AUTOSAR XML (schema 4-3-0)
package /CAN1/ISignalGroup
  36 x i signal group:
    CAN1_SG_AC_BTMS_C1000_0: i-signal=[CAN1_ACAmbTemp, CAN1_ACCabinTemp, CAN1_THCM_Reserve1_Sta, CAN1_THCM_Reserve2_Sta, CAN1_THCM_Reserve3_Sta, CAN1_THCM_Reserve4_Sta], system-signal-group=CAN1_SG_AC_BTMS_C1000_0
    CAN1_SG_AC_BTMS_C1000_1: i-signal=[CAN1_ACFanSpdSta, CAN1_ACMODESta, CAN1_ACPwrSta, CAN1_THCM_Outcycle_Sta, CAN1_THCM_Reserve10_Sta, CAN1_THCM_Reserve11_Sta, CAN1_THCM_Reserve12_Sta, CAN1_THCM_Reserve13_Sta, CAN1_THCM_Reserve5_Sta, CAN1_THCM_Reserve6_Sta, CAN1_THCM_Reserve7_Sta, CAN1_THCM_Reserve8_Sta, CAN1_THCM_Reserve9_Sta], system-signal-group=CAN1_SG_AC_BTMS_C1000_1
    CAN1_SG_AC_BTMS_C1000_2: i-signal=CAN1_THCM_Faultlv_Sta, system-signal-group=CAN1_SG_AC_BTMS_C1000_2
    CAN1_SG_AC_BTMS_C1000_4: i-signal=[CAN1_TM2BFaultCode, CAN1_TM2BFaultLv, CAN1_TM2BInletTemp, CAN1_TM2BOutletTemp, CAN1_TM2BRQPower, CAN1_TM2BTMSHVRlySta, CAN1_TM2BWorkStatus], system-signal-group=CAN1_SG_AC_BTMS_C1000_4
    CAN1_SG_AC_BTMS_C5000_0: i-signal=CAN1_ACTempSetSta, system-signal-group=CAN1_SG_AC_BTMS_C5000_0
    CAN1_SG_ASC1_A: i-signal=CAN1_ASC1KneelingInfo, system-signal-group=CAN1_SG_ASC1_A
    CAN1_SG_EBC1: i-signal=[CAN1_ABSFullyOper, CAN1_ABSOffroadSw, CAN1_ASRBrakeCtrlAtc, CAN1_ASREngCtrlAtc, CAN1_ASRHillHolderSw, CAN1_ASROffroadSw, CAN1_ATCASRInfoSig, CAN1_AcltrInterlockSw, CAN1_AntiLBrakABSAct, CAN1_BrakePedalPos, CAN1_EBSAmWarnLampSta, CAN1_EBSBrakeSw, CAN1_EBSRedWarnLampSta, CAN1_EngAuxShutdownSw, CAN1_EngDerateSw, CAN1_EngRetSel, CAN1_HaltBrakeSw, CAN1_RmAccelEnSw, CAN1_SACtrlBrakeCtrl, CAN1_TractCtrlOvrSw, CAN1_TrailerABSSta, CAN1_TrailerABSWarnSig], system-signal-group=CAN1_SG_EBC1
    CAN1_SG_EBC2: i-signal=[CAN1_FASpeed, CAN1_RelaSpdFALWheel, CAN1_RelaSpdFARWheel, CAN1_RelaSpdRA1LWheel, CAN1_RelaSpdRA1RWheel, CAN1_RelaSpdRA2LWheel, CAN1_RelaSpdRA2RWheel], system-signal-group=CAN1_SG_EBC2
    CAN1_SG_EBC5: i-signal=[CAN1_BrkTempeWarn, CAN1_EmhBrkAct, CAN1_FndBrkUse, CAN1_HaltBrkMode, CAN1_HillHolderMode, CAN1_ParkBrkActuFAct, CAN1_RailroadMode, CAN1_XBRAcltnLimit, CAN1_XBRActtrlMode, CAN1_XBRSysSta], system-signal-group=CAN1_SG_EBC5
    CAN1_SG_ECAS_DM1: i-signal=CAN1_ECASAWarmLampSta, system-signal-group=CAN1_SG_ECAS_DM1
    CAN1_SG_EMC1_EM1: i-signal=[CAN1_EM1CS, CAN1_EM1Cnt, CAN1_EM1OvrCtrlMBrk, CAN1_EM1OvrCtrlMDriv, CAN1_EM1OvrCtrlMPriBrk, CAN1_EM1OvrCtrlMPriDriv, CAN1_EM1ReqTorqHRlsBrk, CAN1_EM1ReqTorqHRlsDri, CAN1_EM1ReqTorqLimBrk, CAN1_EM1ReqTorqLimDriv], system-signal-group=CAN1_SG_EMC1_EM1
    CAN1_SG_FD1_C1000_0: i-signal=[CAN1_AirPressureFC2, CAN1_AirPressurePC3, CAN1_AirPressureRC1], system-signal-group=CAN1_SG_FD1_C1000_0
    CAN1_SG_FD1_C100_0: i-signal=CAN1_VCUEBSRd4BR, system-signal-group=CAN1_SG_FD1_C100_0
    CAN1_SG_FD1_C100_1: i-signal=[CAN1_VCUEBSHBSw, CAN1_VCUEBSHHSw], system-signal-group=CAN1_SG_FD1_C100_1
    CAN1_SG_FD1_C100_2: i-signal=[CAN1_GearFlashInd, CAN1_LVBattLow, CAN1_PweLmtInd, CAN1_VCUBCMBuzzReq, CAN1_VCUDTCCurrCode, CAN1_VCUDTCCurrSta, CAN1_VCUDTCHisCode, CAN1_VCUDTCHisSta, CAN1_VCUKeyStatus, CAN1_VCUWarnInd, CAN1_VCUnoPBInd], system-signal-group=CAN1_SG_FD1_C100_2
    CAN1_SG_FD1_C100_3: i-signal=[CAN1_BrakeSW, CAN1_VCUVehSpd], system-signal-group=CAN1_SG_FD1_C100_3
    CAN1_SG_CGW_FD1_C100_3: i-signal=CAN1_ParkBrakeSW, system-signal-group=CAN1_SG_CGW_FD1_C100_3
    CAN1_SG_FD1_C10_0: i-signal=CAN1_VehActDriveDirect, system-signal-group=CAN1_SG_FD1_C10_0
    CAN1_SG_FD1_C10_1: i-signal=[CAN1_ActEMOutSftSpd, CAN1_ActEMpTrq, CAN1_ActEMpTrqHrls, CAN1_ActMaxAvaEMRecpTrq, CAN1_DrvDemEMRtapTrq, CAN1_EMTrqModeDrvBrk, CAN1_RetSelNonEng, CAN1_SACtrlDev], system-signal-group=CAN1_SG_FD1_C10_1
    CAN1_SG_FD1_C200_0: i-signal=CAN1_SysPowerMode, system-signal-group=CAN1_SG_FD1_C200_0
    CAN1_SG_FD1_C20_0: i-signal=[CAN1_DCCurr, CAN1_DCVol, CAN1_MaxTorqAvail, CAN1_MinTorqAvail], system-signal-group=CAN1_SG_FD1_C20_0
    CAN1_SG_FD1_C250_0: i-signal=[CAN1_EMParasLoss, CAN1_NFricPercTorq], system-signal-group=CAN1_SG_FD1_C250_0
    CAN1_SG_FD1_C5000_0: i-signal=[CAN1_RC1MaxRetSpdP2, CAN1_RC1PctTrqIdleP1, CAN1_RC1PctTrqMaxSpdP2, CAN1_RC1PctTrqP3, CAN1_RC1PctTrqP4, CAN1_RC1PctTrqPekTrqP5, CAN1_RC1RefRetTrq, CAN1_RC1RetCtrlMth, CAN1_RC1RetLocat, CAN1_RC1RetSpdIdleP1, CAN1_RC1RetSpdP3, CAN1_RC1RetSpdP4, CAN1_RC1RetSpdPekTrqP5, CAN1_RC1RetType], system-signal-group=CAN1_SG_FD1_C5000_0
    CAN1_SG_FD1_C5000_1: i-signal=[CAN1_EMDefTrqLmt, CAN1_EMEMRefTorq, CAN1_EMEMSpdP2, CAN1_EMEMSpdP3, CAN1_EMEMSpdP4, CAN1_EMEMSpdP5, CAN1_EMExtRSCtrlUpLmt, CAN1_EMGainEndSpdGvn, CAN1_EMMaxMEngOvrSP7, CAN1_EMMaxMOvrTLmt, CAN1_EMMomOfInertia, CAN1_EMPercTorqIdleP1, CAN1_EMPercTorqP2, CAN1_EMPercTorqP3, CAN1_EMPercTorqP4, CAN1_EMPercTorqP5, CAN1_EMReqSpdCtrlLoLmt, CAN1_EMReqSpdCtrlUpLmt, CAN1_EMReqTrqCtrlLoLmt, CAN1_EMReqTrqCtrlUpLmt, CAN1_EMSpdHIdleP6, CAN1_EMSpdIdleP1, CAN1_EMSupTSC1CtrlPG1, CAN1_EMSupTSC1CtrlPG2, CAN1_EMSupTSC1CtrlPG3, CAN1_EMSupTSC1CtrlPG4, CAN1_EMSupVarRTSC1MSG], system-signal-group=CAN1_SG_FD1_C5000_1
    CAN1_SG_FD1_C50_0: i-signal=CAN1_ActDriveDirect, system-signal-group=CAN1_SG_FD1_C50_0
    CAN1_SG_FD1_C50_1: i-signal=[CAN1_AccPedal1LowSW, CAN1_AccPedalPos1, CAN1_EEC2MSGCS, CAN1_EEC2MSGCnt], system-signal-group=CAN1_SG_FD1_C50_1
    CAN1_SG_FD1_C80_0: i-signal=[CAN1_DLEngaged, CAN1_ShiftPgs], system-signal-group=CAN1_SG_FD1_C80_0
    CAN1_SG_FD1_CE100_0: i-signal=[CAN1_CFGEM1DT0, CAN1_CFGEM1DT1, CAN1_CFGEM1DT2, CAN1_CFGEM1DT3, CAN1_CFGEM1DT4, CAN1_CFGEM1DT5, CAN1_CFGEM1DT6, CAN1_CFGEM1DT7], system-signal-group=CAN1_SG_FD1_CE100_0
    CAN1_SG_FD1_CE100_1: i-signal=[CAN1_CFGEM1BAMPGN, CAN1_CFGEM1BAMRsv, CAN1_CFGEM1BAMTNum, CAN1_CFGEM1BAMTSize, CAN1_CFGEM1Ctrl], system-signal-group=CAN1_SG_FD1_CE100_1
    CAN1_SG_FD1_CE100_2: i-signal=[CAN1_FDC_BCM_DVRSignalL_Cmd, CAN1_FDC_BCM_DVRSignalR_Cmd, CAN1_FDC_BCM_LTurnLp_Cmd, CAN1_FDC_BCM_RTurnLp_Cmd], system-signal-group=CAN1_SG_FD1_CE100_2
    CAN1_SG_HRW: i-signal=[CAN1_WhlSpeed_FL, CAN1_WhlSpeed_FR, CAN1_WhlSpeed_RL, CAN1_WhlSpeed_RR], system-signal-group=CAN1_SG_HRW
    CAN1_SG_TC1: i-signal=[CAN1_DrivDirF, CAN1_DrivDirN, CAN1_DrivDirR, CAN1_LifeCnt, CAN1_TransReqGear], system-signal-group=CAN1_SG_TC1
    CAN1_SG_TPMS1: i-signal=[CAN1_LBIBatWarn, CAN1_LBIPressIndi, CAN1_LBISensorFail, CAN1_LBIWheelTmpIndi, CAN1_LBOBatWarn, CAN1_LBOPressIndi, CAN1_LBOSensorFail, CAN1_LBOWheelTmpIndi, CAN1_LFBatWarn, CAN1_LFPressIndi, CAN1_LFSensorFail, CAN1_LFWheelTmpIndi, CAN1_RBIBatWarn, CAN1_RBIPressIndi, CAN1_RBISensorFail, CAN1_RBIWheelTmpIndi, CAN1_RBOBatWarn, CAN1_RBOPressIndi, CAN1_RBOSensorFail, CAN1_RBOWheelTmpIndi, CAN1_RFBatWarn, CAN1_RFPressIndi, CAN1_RFSensorFail, CAN1_RFWheelTmpIndi, CAN1_TPMSWarnIndi], system-signal-group=CAN1_SG_TPMS1
    CAN1_SG_TPMS2: i-signal=[CAN1_LBIWheelPress, CAN1_LBOWheelPress, CAN1_LFWheelPress, CAN1_RBIWheelPress, CAN1_RBOWheelPress, CAN1_RFWheelPress], system-signal-group=CAN1_SG_TPMS2
    CAN1_SG_TPMS3: i-signal=[CAN1_LBIWheelTemp, CAN1_LBOWheelTemp, CAN1_LFWheelTemp, CAN1_RBIWheelTemp, CAN1_RBOWheelTemp, CAN1_RFWheelTemp], system-signal-group=CAN1_SG_TPMS3
    CAN1_SG_VDC1: i-signal=CAN1_VDCBrakeLightReq, system-signal-group=CAN1_SG_VDC1
package /CAN1/Cluster
  can cluster CAN1: baudrate=500
    can physical channel CAN1: comm-connectors=ConnCAN1
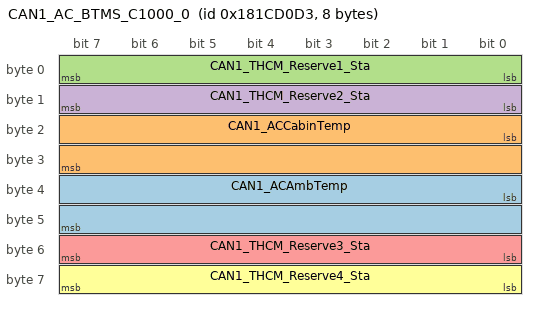
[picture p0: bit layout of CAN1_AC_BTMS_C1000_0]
      frame CAN1_AC_BTMS_C1000_0: id 0x181CD0D3, frame-length=8, can-addressing-mode=EXTENDED, can-fd-frame-support=false, can-frame-rx-behavior=CAN-20, can-frame-tx-behavior=CAN-20
        pdu CAN1_AC_BTMS_C1000_0: length=8, minimum-delay=0.0, transmission-mode-true-timing=cyclic-timing=time-period=1, unused-bit-pattern=0
          mapping CAN1_SG_AC_BTMS_C1000_0: i-signal-group=CAN1_SG_AC_BTMS_C1000_0, start-position=0, transfer-property=PENDING
          signal CAN1_ACAmbTemp: start 32, 16 bit, little-endian, i-signal-type=PRIMITIVE, init-value=constant-reference=Init_CAN1_ACAmbTemp, base-type=uint16, implementation-data-type=uint16, transfer-property=PENDING
          signal CAN1_ACCabinTemp: start 16, 16 bit, little-endian, i-signal-type=PRIMITIVE, init-value=constant-reference=Init_CAN1_ACCabinTemp, base-type=uint16, implementation-data-type=uint16, transfer-property=PENDING
          signal CAN1_THCM_Reserve1_Sta: start 0, 8 bit, little-endian, i-signal-type=PRIMITIVE, init-value=constant-reference=Init_CAN1_THCM_Reserve1_Sta, base-type=uint8, implementation-data-type=uint8, transfer-property=PENDING
          signal CAN1_THCM_Reserve2_Sta: start 8, 8 bit, little-endian, i-signal-type=PRIMITIVE, init-value=constant-reference=Init_CAN1_THCM_Reserve2_Sta, base-type=uint8, implementation-data-type=uint8, transfer-property=PENDING
          signal CAN1_THCM_Reserve3_Sta: start 48, 8 bit, little-endian, i-signal-type=PRIMITIVE, init-value=constant-reference=Init_CAN1_THCM_Reserve3_Sta, base-type=uint8, implementation-data-type=uint8, transfer-property=PENDING
          signal CAN1_THCM_Reserve4_Sta: start 56, 8 bit, little-endian, i-signal-type=PRIMITIVE, init-value=constant-reference=Init_CAN1_THCM_Reserve4_Sta, base-type=uint8, implementation-data-type=uint8, transfer-property=PENDING
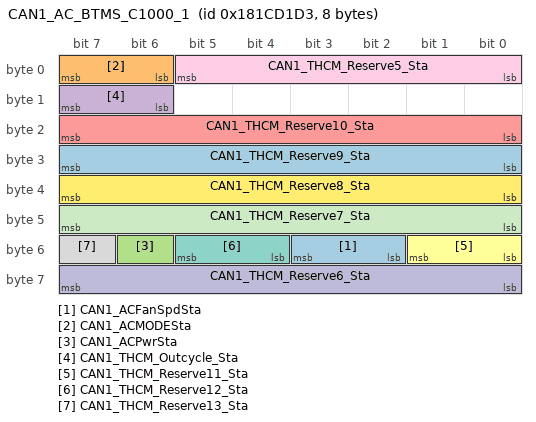
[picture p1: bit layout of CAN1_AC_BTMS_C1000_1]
      frame CAN1_AC_BTMS_C1000_1: id 0x181CD1D3, frame-length=8, can-addressing-mode=EXTENDED, can-fd-frame-support=false, can-frame-rx-behavior=CAN-20, can-frame-tx-behavior=CAN-20
        pdu CAN1_AC_BTMS_C1000_1: length=8, minimum-delay=0.0, transmission-mode-true-timing=cyclic-timing=time-period=1, unused-bit-pattern=0
          mapping CAN1_SG_AC_BTMS_C1000_1: i-signal-group=CAN1_SG_AC_BTMS_C1000_1, start-position=0, transfer-property=PENDING
          signal CAN1_ACFanSpdSta: start 50, 2 bit, little-endian, i-signal-type=PRIMITIVE, init-value=constant-reference=Init_CAN1_ACFanSpdSta, base-type=uint8, implementation-data-type=uint8, transfer-property=PENDING
          signal CAN1_ACMODESta: start 6, 2 bit, little-endian, i-signal-type=PRIMITIVE, init-value=constant-reference=Init_CAN1_ACMODESta, base-type=uint8, implementation-data-type=uint8, transfer-property=PENDING
          signal CAN1_ACPwrSta: start 54, 1 bit, little-endian, i-signal-type=PRIMITIVE, init-value=constant-reference=Init_CAN1_ACPwrSta, base-type=uint8, implementation-data-type=uint8, transfer-property=PENDING
          signal CAN1_THCM_Outcycle_Sta: start 14, 2 bit, little-endian, i-signal-type=PRIMITIVE, init-value=constant-reference=Init_CAN1_THCM_Outcycle_Sta, base-type=uint8, implementation-data-type=uint8, transfer-property=PENDING
          signal CAN1_THCM_Reserve10_Sta: start 16, 8 bit, little-endian, i-signal-type=PRIMITIVE, init-value=constant-reference=Init_CAN1_THCM_Reserve10_Sta, base-type=uint8, implementation-data-type=uint8, transfer-property=PENDING
          signal CAN1_THCM_Reserve11_Sta: start 48, 2 bit, little-endian, i-signal-type=PRIMITIVE, init-value=constant-reference=Init_CAN1_THCM_Reserve11_Sta, base-type=uint8, implementation-data-type=uint8, transfer-property=PENDING
          signal CAN1_THCM_Reserve12_Sta: start 52, 2 bit, little-endian, i-signal-type=PRIMITIVE, init-value=constant-reference=Init_CAN1_THCM_Reserve12_Sta, base-type=uint8, implementation-data-type=uint8, transfer-property=PENDING
          signal CAN1_THCM_Reserve13_Sta: start 55, 1 bit, little-endian, i-signal-type=PRIMITIVE, init-value=constant-reference=Init_CAN1_THCM_Reserve13_Sta, base-type=uint8, implementation-data-type=uint8, transfer-property=PENDING
          signal CAN1_THCM_Reserve5_Sta: start 0, 6 bit, little-endian, i-signal-type=PRIMITIVE, init-value=constant-reference=Init_CAN1_THCM_Reserve5_Sta, base-type=uint8, implementation-data-type=uint8, transfer-property=PENDING
          signal CAN1_THCM_Reserve6_Sta: start 56, 8 bit, little-endian, i-signal-type=PRIMITIVE, init-value=constant-reference=Init_CAN1_THCM_Reserve6_Sta, base-type=uint8, implementation-data-type=uint8, transfer-property=PENDING
          signal CAN1_THCM_Reserve7_Sta: start 40, 8 bit, little-endian, i-signal-type=PRIMITIVE, init-value=constant-reference=Init_CAN1_THCM_Reserve7_Sta, base-type=uint8, implementation-data-type=uint8, transfer-property=PENDING
          signal CAN1_THCM_Reserve8_Sta: start 32, 8 bit, little-endian, i-signal-type=PRIMITIVE, init-value=constant-reference=Init_CAN1_THCM_Reserve8_Sta, base-type=uint8, implementation-data-type=uint8, transfer-property=PENDING
          signal CAN1_THCM_Reserve9_Sta: start 24, 8 bit, little-endian, i-signal-type=PRIMITIVE, init-value=constant-reference=Init_CAN1_THCM_Reserve9_Sta, base-type=uint8, implementation-data-type=uint8, transfer-property=PENDING
      frame CAN1_AC_BTMS_C1000_2: id 0x18FFA219, frame-length=8, can-addressing-mode=EXTENDED, can-fd-frame-support=false, can-frame-rx-behavior=CAN-20, can-frame-tx-behavior=CAN-20
        pdu CAN1_AC_BTMS_C1000_2: length=8, minimum-delay=0.0, transmission-mode-true-timing=cyclic-timing=time-period=1, unused-bit-pattern=0
          mapping CAN1_SG_AC_BTMS_C1000_2: i-signal-group=CAN1_SG_AC_BTMS_C1000_2, start-position=0, transfer-property=PENDING
          signal CAN1_THCM_Faultlv_Sta: start 40, 2 bit, little-endian, i-signal-type=PRIMITIVE, init-value=constant-reference=Init_CAN1_THCM_Faultlv_Sta, base-type=uint8, implementation-data-type=uint8, transfer-property=PENDING
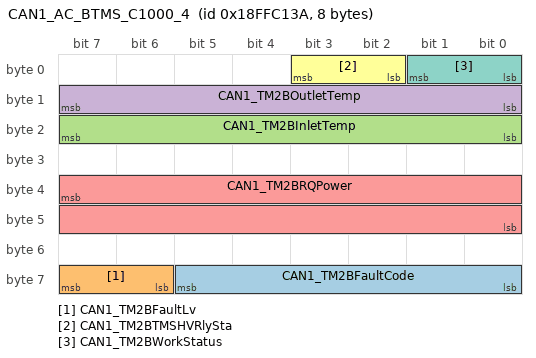
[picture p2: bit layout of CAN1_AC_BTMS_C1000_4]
      frame CAN1_AC_BTMS_C1000_4: id 0x18FFC13A, frame-length=8, can-addressing-mode=EXTENDED, can-fd-frame-support=false, can-frame-rx-behavior=CAN-20, can-frame-tx-behavior=CAN-20
        pdu CAN1_AC_BTMS_C1000_4: length=8, minimum-delay=0.0, transmission-mode-true-timing=cyclic-timing=time-period=1, unused-bit-pattern=0
          mapping CAN1_SG_AC_BTMS_C1000_4: i-signal-group=CAN1_SG_AC_BTMS_C1000_4, start-position=0, transfer-property=PENDING
          signal CAN1_TM2BFaultCode: start 61, 6 bit, big-endian, i-signal-type=PRIMITIVE, init-value=constant-reference=Init_CAN1_TM2BFaultCode, base-type=uint8, implementation-data-type=uint8, transfer-property=PENDING
          signal CAN1_TM2BFaultLv: start 63, 2 bit, big-endian, i-signal-type=PRIMITIVE, init-value=constant-reference=Init_CAN1_TM2BFaultLv, base-type=uint8, implementation-data-type=uint8, transfer-property=PENDING
          signal CAN1_TM2BInletTemp: start 23, 8 bit, big-endian, i-signal-type=PRIMITIVE, init-value=constant-reference=Init_CAN1_TM2BInletTemp, base-type=uint8, implementation-data-type=uint8, transfer-property=PENDING
          signal CAN1_TM2BOutletTemp: start 15, 8 bit, big-endian, i-signal-type=PRIMITIVE, init-value=constant-reference=Init_CAN1_TM2BOutletTemp, base-type=uint8, implementation-data-type=uint8, transfer-property=PENDING
          signal CAN1_TM2BRQPower: start 39, 16 bit, big-endian, i-signal-type=PRIMITIVE, init-value=constant-reference=Init_CAN1_TM2BRQPower, base-type=uint16, implementation-data-type=uint16, transfer-property=PENDING
          signal CAN1_TM2BTMSHVRlySta: start 3, 2 bit, big-endian, i-signal-type=PRIMITIVE, init-value=constant-reference=Init_CAN1_TM2BTMSHVRlySta, base-type=uint8, implementation-data-type=uint8, transfer-property=PENDING
          signal CAN1_TM2BWorkStatus: start 1, 2 bit, big-endian, i-signal-type=PRIMITIVE, init-value=constant-reference=Init_CAN1_TM2BWorkStatus, base-type=uint8, implementation-data-type=uint8, transfer-property=PENDING
      frame CAN1_AC_BTMS_C5000_0: id 0x181CD2D3, frame-length=8, can-addressing-mode=EXTENDED, can-fd-frame-support=false, can-frame-rx-behavior=CAN-20, can-frame-tx-behavior=CAN-20
        pdu CAN1_AC_BTMS_C5000_0: length=8, minimum-delay=0.0, transmission-mode-true-timing=cyclic-timing=time-period=5, unused-bit-pattern=0
          mapping CAN1_SG_AC_BTMS_C5000_0: i-signal-group=CAN1_SG_AC_BTMS_C5000_0, start-position=0, transfer-property=PENDING
          signal CAN1_ACTempSetSta: start 24, 8 bit, little-endian, i-signal-type=PRIMITIVE, init-value=constant-reference=Init_CAN1_ACTempSetSta, base-type=uint8, implementation-data-type=uint8, transfer-property=PENDING
      frame CAN1_ASC1_A: id 0xCFE5A2F, frame-length=8, can-addressing-mode=EXTENDED, can-fd-frame-support=false, can-frame-rx-behavior=CAN-20, can-frame-tx-behavior=CAN-20
        pdu CAN1_ASC1_A: length=8, minimum-delay=0.0, transmission-mode-true-timing=cyclic-timing=time-period=0.1, unused-bit-pattern=0
          mapping CAN1_SG_ASC1_A: i-signal-group=CAN1_SG_ASC1_A, start-position=0, transfer-property=PENDING
          signal CAN1_ASC1KneelingInfo: start 24, 4 bit, little-endian, i-signal-type=PRIMITIVE, init-value=constant-reference=Init_CAN1_ASC1KneelingInfo, base-type=uint8, implementation-data-type=uint8, transfer-property=PENDING
      frame CAN1_DiagFuncReqFT: id 0x7D0, frame-length=8, can-addressing-mode=STANDARD, can-fd-frame-support=false, can-frame-rx-behavior=CAN-20, can-frame-tx-behavior=CAN-20
        n pdu CAN1_DiagFuncReqFT: length=8
      frame CAN1_DiagPhyReqToAC_BTMS: id 0x18DA91F9, frame-length=8, can-addressing-mode=EXTENDED, can-fd-frame-support=false, can-frame-rx-behavior=CAN-20, can-frame-tx-behavior=CAN-20
        n pdu CAN1_DiagPhyReqToAC_BTMS: length=8
      frame CAN1_DiagPhyReqToBSD_L: id 0x18DA84F9, frame-length=8, can-addressing-mode=EXTENDED, can-fd-frame-support=false, can-frame-rx-behavior=CAN-20, can-frame-tx-behavior=CAN-20
        n pdu CAN1_DiagPhyReqToBSD_L: length=8
      frame CAN1_DiagPhyReqToBSD_R: id 0x18DA83F9, frame-length=8, can-addressing-mode=EXTENDED, can-fd-frame-support=false, can-frame-rx-behavior=CAN-20, can-frame-tx-behavior=CAN-20
        n pdu CAN1_DiagPhyReqToBSD_R: length=8
      frame CAN1_DiagPhyReqToECAS: id 0x18DA86F9, frame-length=8, can-addressing-mode=EXTENDED, can-fd-frame-support=false, can-frame-rx-behavior=CAN-20, can-frame-tx-behavior=CAN-20
        n pdu CAN1_DiagPhyReqToECAS: length=8
      frame CAN1_DiagPhyReqToSAS: id 0x18DA85F9, frame-length=8, can-addressing-mode=EXTENDED, can-fd-frame-support=false, can-frame-rx-behavior=CAN-20, can-frame-tx-behavior=CAN-20
        n pdu CAN1_DiagPhyReqToSAS: length=8
      frame CAN1_DiagPhysReqToDMB: id 0x18DA06F9, frame-length=8, can-addressing-mode=EXTENDED, can-fd-frame-support=false, can-frame-rx-behavior=CAN-20, can-frame-tx-behavior=CAN-20
        n pdu CAN1_DiagPhysReqToDMB: length=8
      frame CAN1_DiagPhysReqToEBS3: id 0x18DA0BF9, frame-length=8, can-addressing-mode=EXTENDED, can-fd-frame-support=false, can-frame-rx-behavior=CAN-20, can-frame-tx-behavior=CAN-20
        n pdu CAN1_DiagPhysReqToEBS3: length=8
      frame CAN1_DiagPhysReqToTPMS: id 0x18DA33F9, frame-length=8, can-addressing-mode=EXTENDED, can-fd-frame-support=false, can-frame-rx-behavior=CAN-20, can-frame-tx-behavior=CAN-20
        n pdu CAN1_DiagPhysReqToTPMS: length=8
      frame CAN1_DiagRespFromAC_BTMS: id 0x18DAF991, frame-length=8, can-addressing-mode=EXTENDED, can-fd-frame-support=false, can-frame-rx-behavior=CAN-20, can-frame-tx-behavior=CAN-20
        n pdu CAN1_DiagRespFromAC_BTMS: length=8
      frame CAN1_DiagRespFromBSD_L: id 0x18DAF984, frame-length=8, can-addressing-mode=EXTENDED, can-fd-frame-support=false, can-frame-rx-behavior=CAN-20, can-frame-tx-behavior=CAN-20
        n pdu CAN1_DiagRespFromBSD_L: length=8
      frame CAN1_DiagRespFromBSD_R: id 0x18DAF983, frame-length=8, can-addressing-mode=EXTENDED, can-fd-frame-support=false, can-frame-rx-behavior=CAN-20, can-frame-tx-behavior=CAN-20
        n pdu CAN1_DiagRespFromBSD_R: length=8
      frame CAN1_DiagRespFromDMB: id 0x18DAF906, frame-length=8, can-addressing-mode=EXTENDED, can-fd-frame-support=false, can-frame-rx-behavior=CAN-20, can-frame-tx-behavior=CAN-20
        n pdu CAN1_DiagRespFromDMB: length=8
      frame CAN1_DiagRespFromEBS3: id 0x18DAF90B, frame-length=8, can-addressing-mode=EXTENDED, can-fd-frame-support=false, can-frame-rx-behavior=CAN-20, can-frame-tx-behavior=CAN-20
        n pdu CAN1_DiagRespFromEBS3: length=8
      frame CAN1_DiagRespFromECAS: id 0x18DAF986, frame-length=8, can-addressing-mode=EXTENDED, can-fd-frame-support=false, can-frame-rx-behavior=CAN-20, can-frame-tx-behavior=CAN-20
        n pdu CAN1_DiagRespFromECAS: length=8
      frame CAN1_DiagRespFromSAS: id 0x18DAF985, frame-length=8, can-addressing-mode=EXTENDED, can-fd-frame-support=false, can-frame-rx-behavior=CAN-20, can-frame-tx-behavior=CAN-20
        n pdu CAN1_DiagRespFromSAS: length=8
      frame CAN1_DiagRespFromTPMS: id 0x18DAF933, frame-length=8, can-addressing-mode=EXTENDED, can-fd-frame-support=false, can-frame-rx-behavior=CAN-20, can-frame-tx-behavior=CAN-20
        n pdu CAN1_DiagRespFromTPMS: length=8
      frame CAN1_EBC1: id 0x18F0010B, frame-length=8, can-addressing-mode=EXTENDED, can-fd-frame-support=false, can-frame-rx-behavior=CAN-20, can-frame-tx-behavior=CAN-20
        pdu CAN1_EBC1: length=8, minimum-delay=0.0, transmission-mode-true-timing=cyclic-timing=time-period=0.1, unused-bit-pattern=0
          mapping CAN1_SG_EBC1: i-signal-group=CAN1_SG_EBC1, start-position=0, transfer-property=PENDING
          signal CAN1_ABSFullyOper: start 40, 2 bit, little-endian, i-signal-type=PRIMITIVE, init-value=constant-reference=Init_CAN1_ABSFullyOper, base-type=uint8, implementation-data-type=uint8, transfer-property=PENDING
          signal CAN1_ABSOffroadSw: start 16, 2 bit, little-endian, i-signal-type=PRIMITIVE, init-value=constant-reference=Init_CAN1_ABSOffroadSw, base-type=uint8, implementation-data-type=uint8, transfer-property=PENDING
          signal CAN1_ASRBrakeCtrlAtc: start 2, 2 bit, little-endian, i-signal-type=PRIMITIVE, init-value=constant-reference=Init_CAN1_ASRBrakeCtrlAtc, base-type=uint8, implementation-data-type=uint8, transfer-property=PENDING
          signal CAN1_ASREngCtrlAtc: start 0, 2 bit, little-endian, i-signal-type=PRIMITIVE, init-value=constant-reference=Init_CAN1_ASREngCtrlAtc, base-type=uint8, implementation-data-type=uint8, transfer-property=PENDING
          signal CAN1_ASRHillHolderSw: start 20, 2 bit, little-endian, i-signal-type=PRIMITIVE, init-value=constant-reference=Init_CAN1_ASRHillHolderSw, base-type=uint8, implementation-data-type=uint8, transfer-property=PENDING
          signal CAN1_ASROffroadSw: start 18, 2 bit, little-endian, i-signal-type=PRIMITIVE, init-value=constant-reference=Init_CAN1_ASROffroadSw, base-type=uint8, implementation-data-type=uint8, transfer-property=PENDING
          signal CAN1_ATCASRInfoSig: start 46, 2 bit, little-endian, i-signal-type=PRIMITIVE, init-value=constant-reference=Init_CAN1_ATCASRInfoSig, base-type=uint8, implementation-data-type=uint8, transfer-property=PENDING
          signal CAN1_AcltrInterlockSw: start 24, 2 bit, little-endian, i-signal-type=PRIMITIVE, init-value=constant-reference=Init_CAN1_AcltrInterlockSw, base-type=uint8, implementation-data-type=uint8, transfer-property=PENDING
          signal CAN1_AntiLBrakABSAct: start 4, 2 bit, little-endian, i-signal-type=PRIMITIVE, init-value=constant-reference=Init_CAN1_AntiLBrakABSAct, base-type=uint8, implementation-data-type=uint8, transfer-property=PENDING
          signal CAN1_BrakePedalPos: start 8, 8 bit, little-endian, i-signal-type=PRIMITIVE, init-value=constant-reference=Init_CAN1_BrakePedalPos, base-type=uint8, implementation-data-type=uint8, transfer-property=PENDING
          signal CAN1_EBSAmWarnLampSta: start 44, 2 bit, little-endian, i-signal-type=PRIMITIVE, init-value=constant-reference=Init_CAN1_EBSAmWarnLampSta, base-type=uint8, implementation-data-type=uint8, transfer-property=PENDING
          signal CAN1_EBSBrakeSw: start 6, 2 bit, little-endian, i-signal-type=PRIMITIVE, init-value=constant-reference=Init_CAN1_EBSBrakeSw, base-type=uint8, implementation-data-type=uint8, transfer-property=PENDING
          signal CAN1_EBSRedWarnLampSta: start 42, 2 bit, little-endian, i-signal-type=PRIMITIVE, init-value=constant-reference=Init_CAN1_EBSRedWarnLampSta, base-type=uint8, implementation-data-type=uint8, transfer-property=PENDING
          signal CAN1_EngAuxShutdownSw: start 28, 2 bit, little-endian, i-signal-type=PRIMITIVE, init-value=constant-reference=Init_CAN1_EngAuxShutdownSw, base-type=uint8, implementation-data-type=uint8, transfer-property=PENDING
          signal CAN1_EngDerateSw: start 26, 2 bit, little-endian, i-signal-type=PRIMITIVE, init-value=constant-reference=Init_CAN1_EngDerateSw, base-type=uint8, implementation-data-type=uint8, transfer-property=PENDING
          signal CAN1_EngRetSel: start 32, 8 bit, little-endian, i-signal-type=PRIMITIVE, init-value=constant-reference=Init_CAN1_EngRetSel, base-type=uint8, implementation-data-type=uint8, transfer-property=PENDING
          signal CAN1_HaltBrakeSw: start 58, 2 bit, little-endian, i-signal-type=PRIMITIVE, init-value=constant-reference=Init_CAN1_HaltBrakeSw, base-type=uint8, implementation-data-type=uint8, transfer-property=PENDING
          signal CAN1_RmAccelEnSw: start 30, 2 bit, little-endian, i-signal-type=PRIMITIVE, init-value=constant-reference=Init_CAN1_RmAccelEnSw, base-type=uint8, implementation-data-type=uint8, transfer-property=PENDING
          signal CAN1_SACtrlBrakeCtrl: start 48, 8 bit, little-endian, i-signal-type=PRIMITIVE, init-value=constant-reference=Init_CAN1_SACtrlBrakeCtrl, base-type=uint8, implementation-data-type=uint8, transfer-property=PENDING
          signal CAN1_TractCtrlOvrSw: start 22, 2 bit, little-endian, i-signal-type=PRIMITIVE, init-value=constant-reference=Init_CAN1_TractCtrlOvrSw, base-type=uint8, implementation-data-type=uint8, transfer-property=PENDING
          signal CAN1_TrailerABSSta: start 60, 2 bit, little-endian, i-signal-type=PRIMITIVE, init-value=constant-reference=Init_CAN1_TrailerABSSta, base-type=uint8, implementation-data-type=uint8, transfer-property=PENDING
          signal CAN1_TrailerABSWarnSig: start 62, 2 bit, little-endian, i-signal-type=PRIMITIVE, init-value=constant-reference=Init_CAN1_TrailerABSWarnSig, base-type=uint8, implementation-data-type=uint8, transfer-property=PENDING
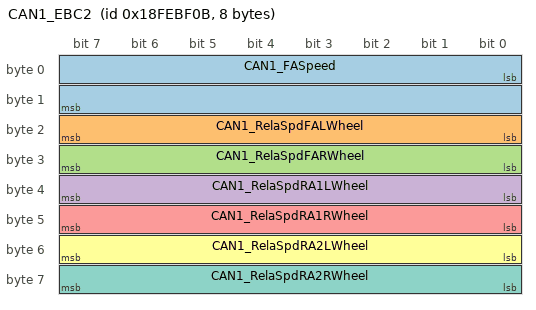
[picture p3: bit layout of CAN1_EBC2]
      frame CAN1_EBC2: id 0x18FEBF0B, frame-length=8, can-addressing-mode=EXTENDED, can-fd-frame-support=false, can-frame-rx-behavior=CAN-20, can-frame-tx-behavior=CAN-20
        pdu CAN1_EBC2: length=8, minimum-delay=0.0, transmission-mode-true-timing=cyclic-timing=time-period=0.1, unused-bit-pattern=0
          mapping CAN1_SG_EBC2: i-signal-group=CAN1_SG_EBC2, start-position=0, transfer-property=PENDING
          signal CAN1_FASpeed: start 0, 16 bit, little-endian, i-signal-type=PRIMITIVE, init-value=constant-reference=Init_CAN1_FASpeed, base-type=uint16, implementation-data-type=uint16, transfer-property=PENDING
          signal CAN1_RelaSpdFALWheel: start 16, 8 bit, little-endian, i-signal-type=PRIMITIVE, init-value=constant-reference=Init_CAN1_RelaSpdFALWheel, base-type=uint8, implementation-data-type=uint8, transfer-property=PENDING
          signal CAN1_RelaSpdFARWheel: start 24, 8 bit, little-endian, i-signal-type=PRIMITIVE, init-value=constant-reference=Init_CAN1_RelaSpdFARWheel, base-type=uint8, implementation-data-type=uint8, transfer-property=PENDING
          signal CAN1_RelaSpdRA1LWheel: start 32, 8 bit, little-endian, i-signal-type=PRIMITIVE, init-value=constant-reference=Init_CAN1_RelaSpdRA1LWheel, base-type=uint8, implementation-data-type=uint8, transfer-property=PENDING
          signal CAN1_RelaSpdRA1RWheel: start 40, 8 bit, little-endian, i-signal-type=PRIMITIVE, init-value=constant-reference=Init_CAN1_RelaSpdRA1RWheel, base-type=uint8, implementation-data-type=uint8, transfer-property=PENDING
          signal CAN1_RelaSpdRA2LWheel: start 48, 8 bit, little-endian, i-signal-type=PRIMITIVE, init-value=constant-reference=Init_CAN1_RelaSpdRA2LWheel, base-type=uint8, implementation-data-type=uint8, transfer-property=PENDING
          signal CAN1_RelaSpdRA2RWheel: start 56, 8 bit, little-endian, i-signal-type=PRIMITIVE, init-value=constant-reference=Init_CAN1_RelaSpdRA2RWheel, base-type=uint8, implementation-data-type=uint8, transfer-property=PENDING
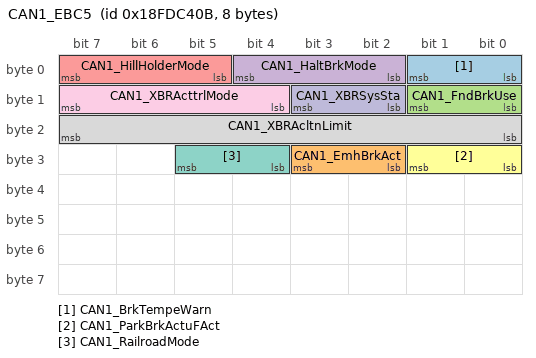
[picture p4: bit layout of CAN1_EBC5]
      frame CAN1_EBC5: id 0x18FDC40B, frame-length=8, can-addressing-mode=EXTENDED, can-fd-frame-support=false, can-frame-rx-behavior=CAN-20, can-frame-tx-behavior=CAN-20
        pdu CAN1_EBC5: length=8, minimum-delay=0.0, transmission-mode-true-timing=cyclic-timing=time-period=0.1, unused-bit-pattern=0
          mapping CAN1_SG_EBC5: i-signal-group=CAN1_SG_EBC5, start-position=0, transfer-property=PENDING
          signal CAN1_BrkTempeWarn: start 0, 2 bit, little-endian, i-signal-type=PRIMITIVE, init-value=constant-reference=Init_CAN1_BrkTempeWarn, base-type=uint8, implementation-data-type=uint8, transfer-property=PENDING
          signal CAN1_EmhBrkAct: start 26, 2 bit, little-endian, i-signal-type=PRIMITIVE, init-value=constant-reference=Init_CAN1_EmhBrkAct, base-type=uint8, implementation-data-type=uint8, transfer-property=PENDING
          signal CAN1_FndBrkUse: start 8, 2 bit, little-endian, i-signal-type=PRIMITIVE, init-value=constant-reference=Init_CAN1_FndBrkUse, base-type=uint8, implementation-data-type=uint8, transfer-property=PENDING
          signal CAN1_HaltBrkMode: start 2, 3 bit, little-endian, i-signal-type=PRIMITIVE, init-value=constant-reference=Init_CAN1_HaltBrkMode, base-type=uint8, implementation-data-type=uint8, transfer-property=PENDING
          signal CAN1_HillHolderMode: start 5, 3 bit, little-endian, i-signal-type=PRIMITIVE, init-value=constant-reference=Init_CAN1_HillHolderMode, base-type=uint8, implementation-data-type=uint8, transfer-property=PENDING
          signal CAN1_ParkBrkActuFAct: start 24, 2 bit, little-endian, i-signal-type=PRIMITIVE, init-value=constant-reference=Init_CAN1_ParkBrkActuFAct, base-type=uint8, implementation-data-type=uint8, transfer-property=PENDING
          signal CAN1_RailroadMode: start 28, 2 bit, little-endian, i-signal-type=PRIMITIVE, init-value=constant-reference=Init_CAN1_RailroadMode, base-type=uint8, implementation-data-type=uint8, transfer-property=PENDING
          signal CAN1_XBRAcltnLimit: start 16, 8 bit, little-endian, i-signal-type=PRIMITIVE, init-value=constant-reference=Init_CAN1_XBRAcltnLimit, base-type=uint8, implementation-data-type=uint8, transfer-property=PENDING
          signal CAN1_XBRActtrlMode: start 12, 4 bit, little-endian, i-signal-type=PRIMITIVE, init-value=constant-reference=Init_CAN1_XBRActtrlMode, base-type=uint8, implementation-data-type=uint8, transfer-property=PENDING
          signal CAN1_XBRSysSta: start 10, 2 bit, little-endian, i-signal-type=PRIMITIVE, init-value=constant-reference=Init_CAN1_XBRSysSta, base-type=uint8, implementation-data-type=uint8, transfer-property=PENDING
      frame CAN1_ECAS_DM1: id 0x18FECA2F, frame-length=8, can-addressing-mode=EXTENDED, can-fd-frame-support=false, can-frame-rx-behavior=CAN-20, can-frame-tx-behavior=CAN-20
        pdu CAN1_ECAS_DM1: length=8, minimum-delay=0.0, transmission-mode-true-timing={cyclic-timing=time-period=0.2, event-controlled-timing={number-of-repetitions=0, repetition-period=0}}, unused-bit-pattern=0
          mapping CAN1_SG_ECAS_DM1: i-signal-group=CAN1_SG_ECAS_DM1, start-position=0, transfer-property=TRIGGERED-ON-CHANGE
          signal CAN1_ECASAWarmLampSta: start 2, 2 bit, little-endian, i-signal-type=PRIMITIVE, init-value=constant-reference=Init_CAN1_ECASAWarmLampSta, base-type=uint8, implementation-data-type=uint8, transfer-property=TRIGGERED-ON-CHANGE
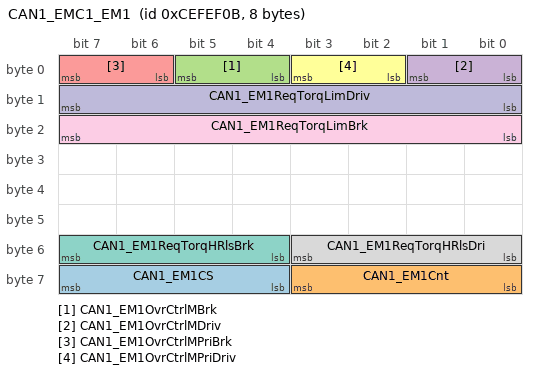
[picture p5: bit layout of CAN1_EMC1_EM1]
      frame CAN1_EMC1_EM1: id 0xCEFEF0B, frame-length=8, can-addressing-mode=EXTENDED, can-fd-frame-support=false, can-frame-rx-behavior=CAN-20, can-frame-tx-behavior=CAN-20
        pdu CAN1_EMC1_EM1: length=8, minimum-delay=0.0, transmission-mode-true-timing=cyclic-timing=time-period=0.1, unused-bit-pattern=0
          mapping CAN1_SG_EMC1_EM1: i-signal-group=CAN1_SG_EMC1_EM1, start-position=0, transfer-property=PENDING
          signal CAN1_EM1CS: start 60, 4 bit, little-endian, i-signal-type=PRIMITIVE, init-value=constant-reference=Init_CAN1_EM1CS, base-type=uint8, implementation-data-type=uint8, transfer-property=PENDING
          signal CAN1_EM1Cnt: start 56, 4 bit, little-endian, i-signal-type=PRIMITIVE, init-value=constant-reference=Init_CAN1_EM1Cnt, base-type=uint8, implementation-data-type=uint8, transfer-property=PENDING
          signal CAN1_EM1OvrCtrlMBrk: start 4, 2 bit, little-endian, i-signal-type=PRIMITIVE, init-value=constant-reference=Init_CAN1_EM1OvrCtrlMBrk, base-type=uint8, implementation-data-type=uint8, transfer-property=PENDING
          signal CAN1_EM1OvrCtrlMDriv: start 0, 2 bit, little-endian, i-signal-type=PRIMITIVE, init-value=constant-reference=Init_CAN1_EM1OvrCtrlMDriv, base-type=uint8, implementation-data-type=uint8, transfer-property=PENDING
          signal CAN1_EM1OvrCtrlMPriBrk: start 6, 2 bit, little-endian, i-signal-type=PRIMITIVE, init-value=constant-reference=Init_CAN1_EM1OvrCtrlMPriBrk, base-type=uint8, implementation-data-type=uint8, transfer-property=PENDING
          signal CAN1_EM1OvrCtrlMPriDriv: start 2, 2 bit, little-endian, i-signal-type=PRIMITIVE, init-value=constant-reference=Init_CAN1_EM1OvrCtrlMPriDriv, base-type=uint8, implementation-data-type=uint8, transfer-property=PENDING
          signal CAN1_EM1ReqTorqHRlsBrk: start 52, 4 bit, little-endian, i-signal-type=PRIMITIVE, init-value=constant-reference=Init_CAN1_EM1ReqTorqHRlsBrk, base-type=uint8, implementation-data-type=uint8, transfer-property=PENDING
          signal CAN1_EM1ReqTorqHRlsDri: start 48, 4 bit, little-endian, i-signal-type=PRIMITIVE, init-value=constant-reference=Init_CAN1_EM1ReqTorqHRlsDri, base-type=uint8, implementation-data-type=uint8, transfer-property=PENDING
          signal CAN1_EM1ReqTorqLimBrk: start 16, 8 bit, little-endian, i-signal-type=PRIMITIVE, init-value=constant-reference=Init_CAN1_EM1ReqTorqLimBrk, base-type=uint8, implementation-data-type=uint8, transfer-property=PENDING
          signal CAN1_EM1ReqTorqLimDriv: start 8, 8 bit, little-endian, i-signal-type=PRIMITIVE, init-value=constant-reference=Init_CAN1_EM1ReqTorqLimDriv, base-type=uint8, implementation-data-type=uint8, transfer-property=PENDING
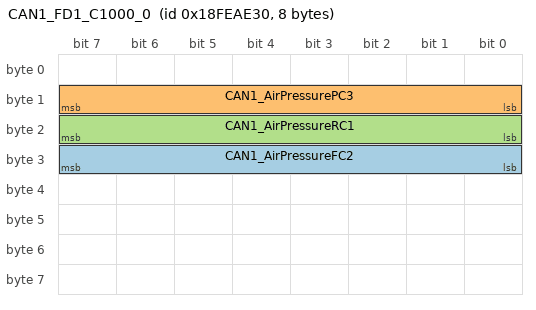
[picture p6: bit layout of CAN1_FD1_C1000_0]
      frame CAN1_FD1_C1000_0: id 0x18FEAE30, frame-length=8, can-addressing-mode=EXTENDED, can-fd-frame-support=false, can-frame-rx-behavior=CAN-20, can-frame-tx-behavior=CAN-20
        pdu CAN1_FD1_C1000_0: length=8, minimum-delay=0.0, transmission-mode-true-timing=cyclic-timing=time-period=1, unused-bit-pattern=0
          mapping CAN1_SG_FD1_C1000_0: i-signal-group=CAN1_SG_FD1_C1000_0, start-position=0, transfer-property=PENDING
          signal CAN1_AirPressureFC2: start 24, 8 bit, little-endian, i-signal-type=PRIMITIVE, init-value=constant-reference=Init_CAN1_AirPressureFC2, base-type=uint8, implementation-data-type=uint8, transfer-property=PENDING
          signal CAN1_AirPressurePC3: start 8, 8 bit, little-endian, i-signal-type=PRIMITIVE, init-value=constant-reference=Init_CAN1_AirPressurePC3, base-type=uint8, implementation-data-type=uint8, transfer-property=PENDING
          signal CAN1_AirPressureRC1: start 16, 8 bit, little-endian, i-signal-type=PRIMITIVE, init-value=constant-reference=Init_CAN1_AirPressureRC1, base-type=uint8, implementation-data-type=uint8, transfer-property=PENDING
      frame CAN1_FD1_C100_0: id 0x18FE4A03, frame-length=8, can-addressing-mode=EXTENDED, can-fd-frame-support=false, can-frame-rx-behavior=CAN-20, can-frame-tx-behavior=CAN-20
        pdu CAN1_FD1_C100_0: length=8, minimum-delay=0.0, transmission-mode-true-timing=cyclic-timing=time-period=0.1, unused-bit-pattern=0
          mapping CAN1_SG_FD1_C100_0: i-signal-group=CAN1_SG_FD1_C100_0, start-position=0, transfer-property=PENDING
          signal CAN1_VCUEBSRd4BR: start 8, 2 bit, little-endian, i-signal-type=PRIMITIVE, init-value=constant-reference=Init_CAN1_VCUEBSRd4BR, base-type=uint8, implementation-data-type=uint8, transfer-property=PENDING
      frame CAN1_FD1_C100_1: id 0x18FF602B, frame-length=8, can-addressing-mode=EXTENDED, can-fd-frame-support=false, can-frame-rx-behavior=CAN-20, can-frame-tx-behavior=CAN-20
        pdu CAN1_FD1_C100_1: length=8, minimum-delay=0.0, transmission-mode-true-timing=cyclic-timing=time-period=0.1, unused-bit-pattern=0
          mapping CAN1_SG_FD1_C100_1: i-signal-group=CAN1_SG_FD1_C100_1, start-position=0, transfer-property=PENDING
          signal CAN1_VCUEBSHBSw: start 6, 2 bit, little-endian, i-signal-type=PRIMITIVE, init-value=constant-reference=Init_CAN1_VCUEBSHBSw, base-type=uint8, implementation-data-type=uint8, transfer-property=PENDING
          signal CAN1_VCUEBSHHSw: start 4, 2 bit, little-endian, i-signal-type=PRIMITIVE, init-value=constant-reference=Init_CAN1_VCUEBSHHSw, base-type=uint8, implementation-data-type=uint8, transfer-property=PENDING
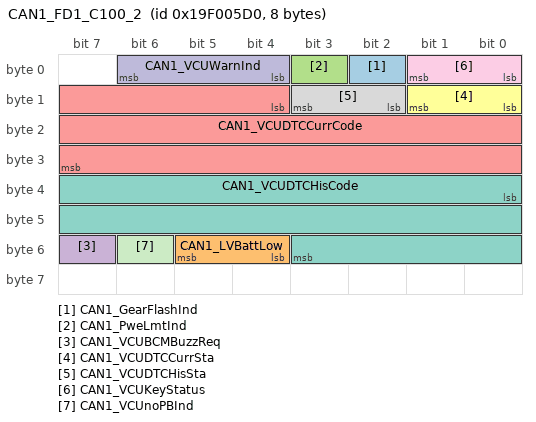
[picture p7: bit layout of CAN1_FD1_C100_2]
      frame CAN1_FD1_C100_2: id 0x19F005D0, frame-length=8, can-addressing-mode=EXTENDED, can-fd-frame-support=false, can-frame-rx-behavior=CAN-20, can-frame-tx-behavior=CAN-20
        pdu CAN1_FD1_C100_2: length=8, minimum-delay=0.0, transmission-mode-true-timing=cyclic-timing=time-period=0.1, unused-bit-pattern=0
          mapping CAN1_SG_FD1_C100_2: i-signal-group=CAN1_SG_FD1_C100_2, start-position=0, transfer-property=PENDING
          signal CAN1_GearFlashInd: start 2, 1 bit, little-endian, i-signal-type=PRIMITIVE, init-value=constant-reference=Init_CAN1_GearFlashInd, base-type=uint8, implementation-data-type=uint8, transfer-property=PENDING
          signal CAN1_LVBattLow: start 52, 2 bit, little-endian, i-signal-type=PRIMITIVE, init-value=constant-reference=Init_CAN1_LVBattLow, base-type=uint8, implementation-data-type=uint8, transfer-property=PENDING
          signal CAN1_PweLmtInd: start 3, 1 bit, little-endian, i-signal-type=PRIMITIVE, init-value=constant-reference=Init_CAN1_PweLmtInd, base-type=uint8, implementation-data-type=uint8, transfer-property=PENDING
          signal CAN1_VCUBCMBuzzReq: start 55, 1 bit, little-endian, i-signal-type=PRIMITIVE, init-value=constant-reference=Init_CAN1_VCUBCMBuzzReq, base-type=uint8, implementation-data-type=uint8, transfer-property=PENDING
          signal CAN1_VCUDTCCurrCode: start 12, 20 bit, little-endian, i-signal-type=PRIMITIVE, init-value=constant-reference=Init_CAN1_VCUDTCCurrCode, base-type=uint32, implementation-data-type=uint32, transfer-property=PENDING
          signal CAN1_VCUDTCCurrSta: start 8, 2 bit, little-endian, i-signal-type=PRIMITIVE, init-value=constant-reference=Init_CAN1_VCUDTCCurrSta, base-type=uint8, implementation-data-type=uint8, transfer-property=PENDING
          signal CAN1_VCUDTCHisCode: start 32, 20 bit, little-endian, i-signal-type=PRIMITIVE, init-value=constant-reference=Init_CAN1_VCUDTCHisCode, base-type=uint32, implementation-data-type=uint32, transfer-property=PENDING
          signal CAN1_VCUDTCHisSta: start 10, 2 bit, little-endian, i-signal-type=PRIMITIVE, init-value=constant-reference=Init_CAN1_VCUDTCHisSta, base-type=uint8, implementation-data-type=uint8, transfer-property=PENDING
          signal CAN1_VCUKeyStatus: start 0, 2 bit, little-endian, i-signal-type=PRIMITIVE, init-value=constant-reference=Init_CAN1_VCUKeyStatus, base-type=uint8, implementation-data-type=uint8, transfer-property=PENDING
          signal CAN1_VCUWarnInd: start 4, 3 bit, little-endian, i-signal-type=PRIMITIVE, init-value=constant-reference=Init_CAN1_VCUWarnInd, base-type=uint8, implementation-data-type=uint8, transfer-property=PENDING
          signal CAN1_VCUnoPBInd: start 54, 1 bit, little-endian, i-signal-type=PRIMITIVE, init-value=constant-reference=Init_CAN1_VCUnoPBInd, base-type=uint8, implementation-data-type=uint8, transfer-property=PENDING
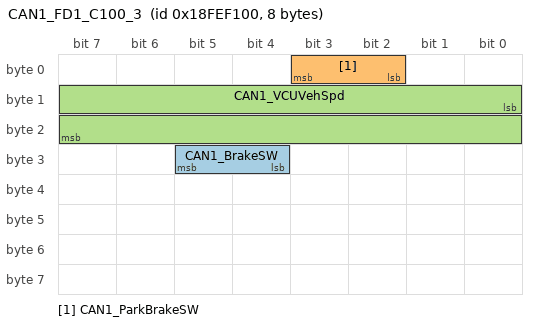
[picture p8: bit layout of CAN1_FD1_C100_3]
      frame CAN1_FD1_C100_3: id 0x18FEF100, frame-length=8, can-addressing-mode=EXTENDED, can-fd-frame-support=false, can-frame-rx-behavior=CAN-20, can-frame-tx-behavior=CAN-20
        pdu CAN1_FD1_C100_3: length=8, minimum-delay=0.0, transmission-mode-true-timing=cyclic-timing=time-period=0.1, unused-bit-pattern=0
          mapping CAN1_SG_FD1_C100_3: i-signal-group=CAN1_SG_FD1_C100_3, start-position=0, transfer-property=PENDING
          mapping CAN1_SG_CGW_FD1_C100_3: i-signal-group=CAN1_SG_CGW_FD1_C100_3, start-position=0, transfer-property=PENDING
          signal CAN1_BrakeSW: start 28, 2 bit, little-endian, i-signal-type=PRIMITIVE, init-value=constant-reference=Init_CAN1_BrakeSW, base-type=uint8, implementation-data-type=uint8, transfer-property=PENDING
          signal CAN1_ParkBrakeSW: start 2, 2 bit, little-endian, i-signal-type=PRIMITIVE, init-value=constant-reference=Init_CAN1_ParkBrakeSW, base-type=uint8, implementation-data-type=uint8, transfer-property=PENDING
          signal CAN1_VCUVehSpd: start 8, 16 bit, little-endian, i-signal-type=PRIMITIVE, init-value=constant-reference=Init_CAN1_VCUVehSpd, base-type=uint16, implementation-data-type=uint16, transfer-property=PENDING
      frame CAN1_FD1_C10_0: id 0xC61D0D1, frame-length=8, can-addressing-mode=EXTENDED, can-fd-frame-support=false, can-frame-rx-behavior=CAN-20, can-frame-tx-behavior=CAN-20
        pdu CAN1_FD1_C10_0: length=8, minimum-delay=0.0, transmission-mode-true-timing=cyclic-timing=time-period=0.01, unused-bit-pattern=0
          mapping CAN1_SG_FD1_C10_0: i-signal-group=CAN1_SG_FD1_C10_0, start-position=0, transfer-property=PENDING
          signal CAN1_VehActDriveDirect: start 0, 2 bit, little-endian, i-signal-type=PRIMITIVE, init-value=constant-reference=Init_CAN1_VehActDriveDirect, base-type=uint8, implementation-data-type=uint8, transfer-property=PENDING
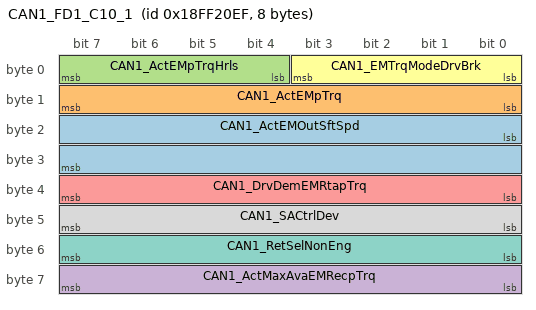
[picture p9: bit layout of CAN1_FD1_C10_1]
      frame CAN1_FD1_C10_1: id 0x18FF20EF, frame-length=8, can-addressing-mode=EXTENDED, can-fd-frame-support=false, can-frame-rx-behavior=CAN-20, can-frame-tx-behavior=CAN-20
        pdu CAN1_FD1_C10_1: length=8, minimum-delay=0.0, transmission-mode-true-timing=cyclic-timing=time-period=0.01, unused-bit-pattern=0
          mapping CAN1_SG_FD1_C10_1: i-signal-group=CAN1_SG_FD1_C10_1, start-position=0, transfer-property=PENDING
          signal CAN1_ActEMOutSftSpd: start 16, 16 bit, little-endian, i-signal-type=PRIMITIVE, init-value=constant-reference=Init_CAN1_ActEMOutSftSpd, base-type=uint16, implementation-data-type=uint16, transfer-property=PENDING
          signal CAN1_ActEMpTrq: start 8, 8 bit, little-endian, i-signal-type=PRIMITIVE, init-value=constant-reference=Init_CAN1_ActEMpTrq, base-type=uint8, implementation-data-type=uint8, transfer-property=PENDING
          signal CAN1_ActEMpTrqHrls: start 4, 4 bit, little-endian, i-signal-type=PRIMITIVE, init-value=constant-reference=Init_CAN1_ActEMpTrqHrls, base-type=uint8, implementation-data-type=uint8, transfer-property=PENDING
          signal CAN1_ActMaxAvaEMRecpTrq: start 56, 8 bit, little-endian, i-signal-type=PRIMITIVE, init-value=constant-reference=Init_CAN1_ActMaxAvaEMRecpTrq, base-type=uint8, implementation-data-type=uint8, transfer-property=PENDING
          signal CAN1_DrvDemEMRtapTrq: start 32, 8 bit, little-endian, i-signal-type=PRIMITIVE, init-value=constant-reference=Init_CAN1_DrvDemEMRtapTrq, base-type=uint8, implementation-data-type=uint8, transfer-property=PENDING
          signal CAN1_EMTrqModeDrvBrk: start 0, 4 bit, little-endian, i-signal-type=PRIMITIVE, init-value=constant-reference=Init_CAN1_EMTrqModeDrvBrk, base-type=uint8, implementation-data-type=uint8, transfer-property=PENDING
          signal CAN1_RetSelNonEng: start 48, 8 bit, little-endian, i-signal-type=PRIMITIVE, init-value=constant-reference=Init_CAN1_RetSelNonEng, base-type=uint8, implementation-data-type=uint8, transfer-property=PENDING
          signal CAN1_SACtrlDev: start 40, 8 bit, little-endian, i-signal-type=PRIMITIVE, init-value=constant-reference=Init_CAN1_SACtrlDev, base-type=uint8, implementation-data-type=uint8, transfer-property=PENDING
      frame CAN1_FD1_C200_0: id 0x18F003EF, frame-length=8, can-addressing-mode=EXTENDED, can-fd-frame-support=false, can-frame-rx-behavior=CAN-20, can-frame-tx-behavior=CAN-20
        pdu CAN1_FD1_C200_0: length=8, minimum-delay=0.0, transmission-mode-true-timing=cyclic-timing=time-period=0.2, unused-bit-pattern=0
          mapping CAN1_SG_FD1_C200_0: i-signal-group=CAN1_SG_FD1_C200_0, start-position=0, transfer-property=PENDING
          signal CAN1_SysPowerMode: start 0, 4 bit, little-endian, i-signal-type=PRIMITIVE, init-value=constant-reference=Init_CAN1_SysPowerMode, base-type=uint8, implementation-data-type=uint8, transfer-property=PENDING
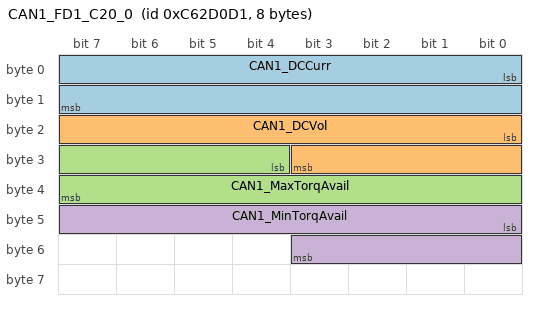
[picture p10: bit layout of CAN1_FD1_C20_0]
      frame CAN1_FD1_C20_0: id 0xC62D0D1, frame-length=8, can-addressing-mode=EXTENDED, can-fd-frame-support=false, can-frame-rx-behavior=CAN-20, can-frame-tx-behavior=CAN-20
        pdu CAN1_FD1_C20_0: length=8, minimum-delay=0.0, transmission-mode-true-timing=cyclic-timing=time-period=0.02, unused-bit-pattern=0
          mapping CAN1_SG_FD1_C20_0: i-signal-group=CAN1_SG_FD1_C20_0, start-position=0, transfer-property=PENDING
          signal CAN1_DCCurr: start 0, 16 bit, little-endian, i-signal-type=PRIMITIVE, init-value=constant-reference=Init_CAN1_DCCurr, base-type=uint16, implementation-data-type=uint16, transfer-property=PENDING
          signal CAN1_DCVol: start 16, 12 bit, little-endian, i-signal-type=PRIMITIVE, init-value=constant-reference=Init_CAN1_DCVol, base-type=uint16, implementation-data-type=uint16, transfer-property=PENDING
          signal CAN1_MaxTorqAvail: start 28, 12 bit, little-endian, i-signal-type=PRIMITIVE, init-value=constant-reference=Init_CAN1_MaxTorqAvail, base-type=uint16, implementation-data-type=uint16, transfer-property=PENDING
          signal CAN1_MinTorqAvail: start 40, 12 bit, little-endian, i-signal-type=PRIMITIVE, init-value=constant-reference=Init_CAN1_MinTorqAvail, base-type=uint16, implementation-data-type=uint16, transfer-property=PENDING
      frame CAN1_FD1_C250_0: id 0x18FEDFEF, frame-length=8, can-addressing-mode=EXTENDED, can-fd-frame-support=false, can-frame-rx-behavior=CAN-20, can-frame-tx-behavior=CAN-20
        pdu CAN1_FD1_C250_0: length=8, minimum-delay=0.0, transmission-mode-true-timing=cyclic-timing=time-period=0.25, unused-bit-pattern=0
          mapping CAN1_SG_FD1_C250_0: i-signal-group=CAN1_SG_FD1_C250_0, start-position=0, transfer-property=PENDING
          signal CAN1_EMParasLoss: start 32, 8 bit, little-endian, i-signal-type=PRIMITIVE, init-value=constant-reference=Init_CAN1_EMParasLoss, base-type=uint8, implementation-data-type=uint8, transfer-property=PENDING
          signal CAN1_NFricPercTorq: start 0, 8 bit, little-endian, i-signal-type=PRIMITIVE, init-value=constant-reference=Init_CAN1_NFricPercTorq, base-type=uint8, implementation-data-type=uint8, transfer-property=PENDING
      frame CAN1_FD1_C5000_0: id 0x18FEE1EF, frame-length=19, can-addressing-mode=EXTENDED, can-fd-frame-support=false, can-frame-rx-behavior=CAN-20, can-frame-tx-behavior=CAN-20
        pdu CAN1_FD1_C5000_0: length=19, minimum-delay=0.0, transmission-mode-true-timing=cyclic-timing=time-period=5, unused-bit-pattern=0
          mapping CAN1_SG_FD1_C5000_0: i-signal-group=CAN1_SG_FD1_C5000_0, start-position=0, transfer-property=PENDING
          signal CAN1_RC1MaxRetSpdP2: start 40, 16 bit, little-endian, i-signal-type=PRIMITIVE, init-value=constant-reference=Init_CAN1_RC1MaxRetSpdP2, base-type=uint16, implementation-data-type=uint16, transfer-property=PENDING
          signal CAN1_RC1PctTrqIdleP1: start 32, 8 bit, little-endian, i-signal-type=PRIMITIVE, init-value=constant-reference=Init_CAN1_RC1PctTrqIdleP1, base-type=uint8, implementation-data-type=uint8, transfer-property=PENDING
          signal CAN1_RC1PctTrqMaxSpdP2: start 56, 8 bit, little-endian, i-signal-type=PRIMITIVE, init-value=constant-reference=Init_CAN1_RC1PctTrqMaxSpdP2, base-type=uint8, implementation-data-type=uint8, transfer-property=PENDING
          signal CAN1_RC1PctTrqP3: start 80, 8 bit, little-endian, i-signal-type=PRIMITIVE, init-value=constant-reference=Init_CAN1_RC1PctTrqP3, base-type=uint8, implementation-data-type=uint8, transfer-property=PENDING
          signal CAN1_RC1PctTrqP4: start 104, 8 bit, little-endian, i-signal-type=PRIMITIVE, init-value=constant-reference=Init_CAN1_RC1PctTrqP4, base-type=uint8, implementation-data-type=uint8, transfer-property=PENDING
          signal CAN1_RC1PctTrqPekTrqP5: start 144, 8 bit, little-endian, i-signal-type=PRIMITIVE, init-value=constant-reference=Init_CAN1_RC1PctTrqPekTrqP5, base-type=uint8, implementation-data-type=uint8, transfer-property=PENDING
          signal CAN1_RC1RefRetTrq: start 128, 16 bit, little-endian, i-signal-type=PRIMITIVE, init-value=constant-reference=Init_CAN1_RC1RefRetTrq, base-type=uint16, implementation-data-type=uint16, transfer-property=PENDING
          signal CAN1_RC1RetCtrlMth: start 8, 8 bit, little-endian, i-signal-type=PRIMITIVE, init-value=constant-reference=Init_CAN1_RC1RetCtrlMth, base-type=uint8, implementation-data-type=uint8, transfer-property=PENDING
          signal CAN1_RC1RetLocat: start 4, 4 bit, little-endian, i-signal-type=PRIMITIVE, init-value=constant-reference=Init_CAN1_RC1RetLocat, base-type=uint8, implementation-data-type=uint8, transfer-property=PENDING
          signal CAN1_RC1RetSpdIdleP1: start 16, 16 bit, little-endian, i-signal-type=PRIMITIVE, init-value=constant-reference=Init_CAN1_RC1RetSpdIdleP1, base-type=uint16, implementation-data-type=uint16, transfer-property=PENDING
          signal CAN1_RC1RetSpdP3: start 64, 16 bit, little-endian, i-signal-type=PRIMITIVE, init-value=constant-reference=Init_CAN1_RC1RetSpdP3, base-type=uint16, implementation-data-type=uint16, transfer-property=PENDING
          signal CAN1_RC1RetSpdP4: start 88, 16 bit, little-endian, i-signal-type=PRIMITIVE, init-value=constant-reference=Init_CAN1_RC1RetSpdP4, base-type=uint16, implementation-data-type=uint16, transfer-property=PENDING
          signal CAN1_RC1RetSpdPekTrqP5: start 112, 16 bit, little-endian, i-signal-type=PRIMITIVE, init-value=constant-reference=Init_CAN1_RC1RetSpdPekTrqP5, base-type=uint16, implementation-data-type=uint16, transfer-property=PENDING
          signal CAN1_RC1RetType: start 0, 4 bit, little-endian, i-signal-type=PRIMITIVE, init-value=constant-reference=Init_CAN1_RC1RetType, base-type=uint8, implementation-data-type=uint8, transfer-property=PENDING
      frame CAN1_FD1_C5000_1: id 0x18FEE3EF, frame-length=39, can-addressing-mode=EXTENDED, can-fd-frame-support=false, can-frame-rx-behavior=CAN-20, can-frame-tx-behavior=CAN-20
        pdu CAN1_FD1_C5000_1: length=39, minimum-delay=0.0, transmission-mode-true-timing=cyclic-timing=time-period=5, unused-bit-pattern=0
          mapping CAN1_SG_FD1_C5000_1: i-signal-group=CAN1_SG_FD1_C5000_1, start-position=0, transfer-property=PENDING
          signal CAN1_EMDefTrqLmt: start 256, 16 bit, little-endian, i-signal-type=PRIMITIVE, init-value=constant-reference=Init_CAN1_EMDefTrqLmt, base-type=uint16, implementation-data-type=uint16, transfer-property=PENDING
          signal CAN1_EMEMRefTorq: start 152, 16 bit, little-endian, i-signal-type=PRIMITIVE, init-value=constant-reference=Init_CAN1_EMEMRefTorq, base-type=uint16, implementation-data-type=uint16, transfer-property=PENDING
          signal CAN1_EMEMSpdP2: start 24, 16 bit, little-endian, i-signal-type=PRIMITIVE, init-value=constant-reference=Init_CAN1_EMEMSpdP2, base-type=uint16, implementation-data-type=uint16, transfer-property=PENDING
          signal CAN1_EMEMSpdP3: start 48, 16 bit, little-endian, i-signal-type=PRIMITIVE, init-value=constant-reference=Init_CAN1_EMEMSpdP3, base-type=uint16, implementation-data-type=uint16, transfer-property=PENDING
          signal CAN1_EMEMSpdP4: start 72, 16 bit, little-endian, i-signal-type=PRIMITIVE, init-value=constant-reference=Init_CAN1_EMEMSpdP4, base-type=uint16, implementation-data-type=uint16, transfer-property=PENDING
          signal CAN1_EMEMSpdP5: start 96, 16 bit, little-endian, i-signal-type=PRIMITIVE, init-value=constant-reference=Init_CAN1_EMEMSpdP5, base-type=uint16, implementation-data-type=uint16, transfer-property=PENDING
          signal CAN1_EMExtRSCtrlUpLmt: start 224, 16 bit, little-endian, i-signal-type=PRIMITIVE, init-value=constant-reference=Init_CAN1_EMExtRSCtrlUpLmt, base-type=uint16, implementation-data-type=uint16, transfer-property=PENDING
          signal CAN1_EMGainEndSpdGvn: start 136, 16 bit, little-endian, i-signal-type=PRIMITIVE, init-value=constant-reference=Init_CAN1_EMGainEndSpdGvn, base-type=uint16, implementation-data-type=uint16, transfer-property=PENDING
          signal CAN1_EMMaxMEngOvrSP7: start 168, 16 bit, little-endian, i-signal-type=PRIMITIVE, init-value=constant-reference=Init_CAN1_EMMaxMEngOvrSP7, base-type=uint16, implementation-data-type=uint16, transfer-property=PENDING
          signal CAN1_EMMaxMOvrTLmt: start 184, 8 bit, little-endian, i-signal-type=PRIMITIVE, init-value=constant-reference=Init_CAN1_EMMaxMOvrTLmt, base-type=uint8, implementation-data-type=uint8, transfer-property=PENDING
          signal CAN1_EMMomOfInertia: start 240, 16 bit, little-endian, i-signal-type=PRIMITIVE, init-value=constant-reference=Init_CAN1_EMMomOfInertia, base-type=uint16, implementation-data-type=uint16, transfer-property=PENDING
          signal CAN1_EMPercTorqIdleP1: start 16, 8 bit, little-endian, i-signal-type=PRIMITIVE, init-value=constant-reference=Init_CAN1_EMPercTorqIdleP1, base-type=uint8, implementation-data-type=uint8, transfer-property=PENDING
          signal CAN1_EMPercTorqP2: start 40, 8 bit, little-endian, i-signal-type=PRIMITIVE, init-value=constant-reference=Init_CAN1_EMPercTorqP2, base-type=uint8, implementation-data-type=uint8, transfer-property=PENDING
          signal CAN1_EMPercTorqP3: start 64, 8 bit, little-endian, i-signal-type=PRIMITIVE, init-value=constant-reference=Init_CAN1_EMPercTorqP3, base-type=uint8, implementation-data-type=uint8, transfer-property=PENDING
          signal CAN1_EMPercTorqP4: start 88, 8 bit, little-endian, i-signal-type=PRIMITIVE, init-value=constant-reference=Init_CAN1_EMPercTorqP4, base-type=uint8, implementation-data-type=uint8, transfer-property=PENDING
          signal CAN1_EMPercTorqP5: start 112, 8 bit, little-endian, i-signal-type=PRIMITIVE, init-value=constant-reference=Init_CAN1_EMPercTorqP5, base-type=uint8, implementation-data-type=uint8, transfer-property=PENDING
          signal CAN1_EMReqSpdCtrlLoLmt: start 192, 8 bit, little-endian, i-signal-type=PRIMITIVE, init-value=constant-reference=Init_CAN1_EMReqSpdCtrlLoLmt, base-type=uint8, implementation-data-type=uint8, transfer-property=PENDING
          signal CAN1_EMReqSpdCtrlUpLmt: start 200, 8 bit, little-endian, i-signal-type=PRIMITIVE, init-value=constant-reference=Init_CAN1_EMReqSpdCtrlUpLmt, base-type=uint8, implementation-data-type=uint8, transfer-property=PENDING
          signal CAN1_EMReqTrqCtrlLoLmt: start 208, 8 bit, little-endian, i-signal-type=PRIMITIVE, init-value=constant-reference=Init_CAN1_EMReqTrqCtrlLoLmt, base-type=uint8, implementation-data-type=uint8, transfer-property=PENDING
          signal CAN1_EMReqTrqCtrlUpLmt: start 216, 8 bit, little-endian, i-signal-type=PRIMITIVE, init-value=constant-reference=Init_CAN1_EMReqTrqCtrlUpLmt, base-type=uint8, implementation-data-type=uint8, transfer-property=PENDING
          signal CAN1_EMSpdHIdleP6: start 120, 16 bit, little-endian, i-signal-type=PRIMITIVE, init-value=constant-reference=Init_CAN1_EMSpdHIdleP6, base-type=uint16, implementation-data-type=uint16, transfer-property=PENDING
          signal CAN1_EMSpdIdleP1: start 0, 16 bit, little-endian, i-signal-type=PRIMITIVE, init-value=constant-reference=Init_CAN1_EMSpdIdleP1, base-type=uint16, implementation-data-type=uint16, transfer-property=PENDING
          signal CAN1_EMSupTSC1CtrlPG1: start 280, 8 bit, little-endian, i-signal-type=PRIMITIVE, init-value=constant-reference=Init_CAN1_EMSupTSC1CtrlPG1, base-type=uint8, implementation-data-type=uint8, transfer-property=PENDING
          signal CAN1_EMSupTSC1CtrlPG2: start 288, 8 bit, little-endian, i-signal-type=PRIMITIVE, init-value=constant-reference=Init_CAN1_EMSupTSC1CtrlPG2, base-type=uint8, implementation-data-type=uint8, transfer-property=PENDING
          signal CAN1_EMSupTSC1CtrlPG3: start 296, 8 bit, little-endian, i-signal-type=PRIMITIVE, init-value=constant-reference=Init_CAN1_EMSupTSC1CtrlPG3, base-type=uint8, implementation-data-type=uint8, transfer-property=PENDING
          signal CAN1_EMSupTSC1CtrlPG4: start 304, 8 bit, little-endian, i-signal-type=PRIMITIVE, init-value=constant-reference=Init_CAN1_EMSupTSC1CtrlPG4, base-type=uint8, implementation-data-type=uint8, transfer-property=PENDING
          signal CAN1_EMSupVarRTSC1MSG: start 272, 8 bit, little-endian, i-signal-type=PRIMITIVE, init-value=constant-reference=Init_CAN1_EMSupVarRTSC1MSG, base-type=uint8, implementation-data-type=uint8, transfer-property=PENDING
      frame CAN1_FD1_C50_0: id 0x18F00503, frame-length=8, can-addressing-mode=EXTENDED, can-fd-frame-support=false, can-frame-rx-behavior=CAN-20, can-frame-tx-behavior=CAN-20
        pdu CAN1_FD1_C50_0: length=8, minimum-delay=0.0, transmission-mode-true-timing=cyclic-timing=time-period=0.05, unused-bit-pattern=0
          mapping CAN1_SG_FD1_C50_0: i-signal-group=CAN1_SG_FD1_C50_0, start-position=0, transfer-property=PENDING
          signal CAN1_ActDriveDirect: start 24, 8 bit, little-endian, i-signal-type=PRIMITIVE, init-value=constant-reference=Init_CAN1_ActDriveDirect, base-type=uint8, implementation-data-type=uint8, transfer-property=PENDING
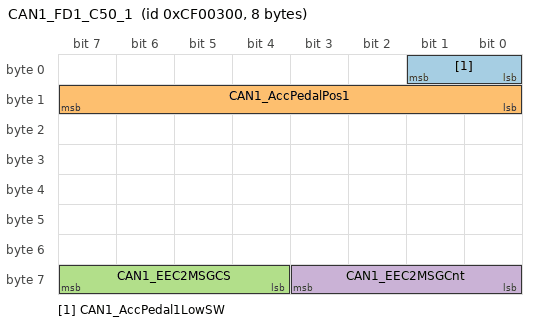
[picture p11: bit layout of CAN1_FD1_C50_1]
      frame CAN1_FD1_C50_1: id 0xCF00300, frame-length=8, can-addressing-mode=EXTENDED, can-fd-frame-support=false, can-frame-rx-behavior=CAN-20, can-frame-tx-behavior=CAN-20
        pdu CAN1_FD1_C50_1: length=8, minimum-delay=0.0, transmission-mode-true-timing=cyclic-timing=time-period=0.05, unused-bit-pattern=0
          mapping CAN1_SG_FD1_C50_1: i-signal-group=CAN1_SG_FD1_C50_1, start-position=0, transfer-property=PENDING
          signal CAN1_AccPedal1LowSW: start 0, 2 bit, little-endian, i-signal-type=PRIMITIVE, init-value=constant-reference=Init_CAN1_AccPedal1LowSW, base-type=uint8, implementation-data-type=uint8, transfer-property=PENDING
          signal CAN1_AccPedalPos1: start 8, 8 bit, little-endian, i-signal-type=PRIMITIVE, init-value=constant-reference=Init_CAN1_AccPedalPos1, base-type=uint8, implementation-data-type=uint8, transfer-property=PENDING
          signal CAN1_EEC2MSGCS: start 60, 4 bit, little-endian, i-signal-type=PRIMITIVE, init-value=constant-reference=Init_CAN1_EEC2MSGCS, base-type=uint8, implementation-data-type=uint8, transfer-property=PENDING
          signal CAN1_EEC2MSGCnt: start 56, 4 bit, little-endian, i-signal-type=PRIMITIVE, init-value=constant-reference=Init_CAN1_EEC2MSGCnt, base-type=uint8, implementation-data-type=uint8, transfer-property=PENDING
      frame CAN1_FD1_C80_0: id 0x18F00203, frame-length=8, can-addressing-mode=EXTENDED, can-fd-frame-support=false, can-frame-rx-behavior=CAN-20, can-frame-tx-behavior=CAN-20
        pdu CAN1_FD1_C80_0: length=8, minimum-delay=0.0, transmission-mode-true-timing=cyclic-timing=time-period=0.08, unused-bit-pattern=0
          mapping CAN1_SG_FD1_C80_0: i-signal-group=CAN1_SG_FD1_C80_0, start-position=0, transfer-property=PENDING
          signal CAN1_DLEngaged: start 0, 2 bit, little-endian, i-signal-type=PRIMITIVE, init-value=constant-reference=Init_CAN1_DLEngaged, base-type=uint8, implementation-data-type=uint8, transfer-property=PENDING
          signal CAN1_ShiftPgs: start 4, 2 bit, little-endian, i-signal-type=PRIMITIVE, init-value=constant-reference=Init_CAN1_ShiftPgs, base-type=uint8, implementation-data-type=uint8, transfer-property=PENDING
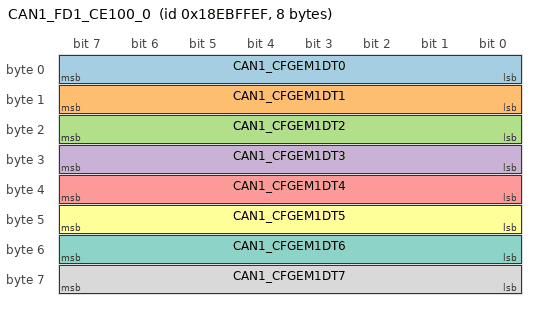
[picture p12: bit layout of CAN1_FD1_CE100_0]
      frame CAN1_FD1_CE100_0: id 0x18EBFFEF, frame-length=8, can-addressing-mode=EXTENDED, can-fd-frame-support=false, can-frame-rx-behavior=CAN-20, can-frame-tx-behavior=CAN-20
        pdu CAN1_FD1_CE100_0: length=8, minimum-delay=0.0, transmission-mode-true-timing=event-controlled-timing={number-of-repetitions=0, repetition-period=0}, unused-bit-pattern=0
          mapping CAN1_SG_FD1_CE100_0: i-signal-group=CAN1_SG_FD1_CE100_0, start-position=0, transfer-property=TRIGGERED
          signal CAN1_CFGEM1DT0: start 0, 8 bit, little-endian, i-signal-type=PRIMITIVE, init-value=constant-reference=Init_CAN1_CFGEM1DT0, base-type=uint8, implementation-data-type=uint8, transfer-property=TRIGGERED
          signal CAN1_CFGEM1DT1: start 8, 8 bit, little-endian, i-signal-type=PRIMITIVE, init-value=constant-reference=Init_CAN1_CFGEM1DT1, base-type=uint8, implementation-data-type=uint8, transfer-property=TRIGGERED
          signal CAN1_CFGEM1DT2: start 16, 8 bit, little-endian, i-signal-type=PRIMITIVE, init-value=constant-reference=Init_CAN1_CFGEM1DT2, base-type=uint8, implementation-data-type=uint8, transfer-property=TRIGGERED
          signal CAN1_CFGEM1DT3: start 24, 8 bit, little-endian, i-signal-type=PRIMITIVE, init-value=constant-reference=Init_CAN1_CFGEM1DT3, base-type=uint8, implementation-data-type=uint8, transfer-property=TRIGGERED
          signal CAN1_CFGEM1DT4: start 32, 8 bit, little-endian, i-signal-type=PRIMITIVE, init-value=constant-reference=Init_CAN1_CFGEM1DT4, base-type=uint8, implementation-data-type=uint8, transfer-property=TRIGGERED
          signal CAN1_CFGEM1DT5: start 40, 8 bit, little-endian, i-signal-type=PRIMITIVE, init-value=constant-reference=Init_CAN1_CFGEM1DT5, base-type=uint8, implementation-data-type=uint8, transfer-property=TRIGGERED
          signal CAN1_CFGEM1DT6: start 48, 8 bit, little-endian, i-signal-type=PRIMITIVE, init-value=constant-reference=Init_CAN1_CFGEM1DT6, base-type=uint8, implementation-data-type=uint8, transfer-property=TRIGGERED
          signal CAN1_CFGEM1DT7: start 56, 8 bit, little-endian, i-signal-type=PRIMITIVE, init-value=constant-reference=Init_CAN1_CFGEM1DT7, base-type=uint8, implementation-data-type=uint8, transfer-property=TRIGGERED
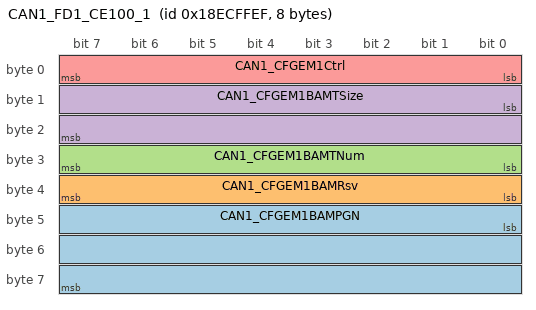
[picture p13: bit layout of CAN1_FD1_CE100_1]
      frame CAN1_FD1_CE100_1: id 0x18ECFFEF, frame-length=8, can-addressing-mode=EXTENDED, can-fd-frame-support=false, can-frame-rx-behavior=CAN-20, can-frame-tx-behavior=CAN-20
        pdu CAN1_FD1_CE100_1: length=8, minimum-delay=0.0, transmission-mode-true-timing=event-controlled-timing={number-of-repetitions=0, repetition-period=0}, unused-bit-pattern=0
          mapping CAN1_SG_FD1_CE100_1: i-signal-group=CAN1_SG_FD1_CE100_1, start-position=0, transfer-property=TRIGGERED
          signal CAN1_CFGEM1BAMPGN: start 40, 24 bit, little-endian, i-signal-type=PRIMITIVE, init-value=constant-reference=Init_CAN1_CFGEM1BAMPGN, base-type=uint32, implementation-data-type=uint32, transfer-property=TRIGGERED
          signal CAN1_CFGEM1BAMRsv: start 32, 8 bit, little-endian, i-signal-type=PRIMITIVE, init-value=constant-reference=Init_CAN1_CFGEM1BAMRsv, base-type=uint8, implementation-data-type=uint8, transfer-property=TRIGGERED
          signal CAN1_CFGEM1BAMTNum: start 24, 8 bit, little-endian, i-signal-type=PRIMITIVE, init-value=constant-reference=Init_CAN1_CFGEM1BAMTNum, base-type=uint8, implementation-data-type=uint8, transfer-property=TRIGGERED
          signal CAN1_CFGEM1BAMTSize: start 8, 16 bit, little-endian, i-signal-type=PRIMITIVE, init-value=constant-reference=Init_CAN1_CFGEM1BAMTSize, base-type=uint16, implementation-data-type=uint16, transfer-property=TRIGGERED
          signal CAN1_CFGEM1Ctrl: start 0, 8 bit, little-endian, i-signal-type=PRIMITIVE, init-value=constant-reference=Init_CAN1_CFGEM1Ctrl, base-type=uint8, implementation-data-type=uint8, transfer-property=TRIGGERED
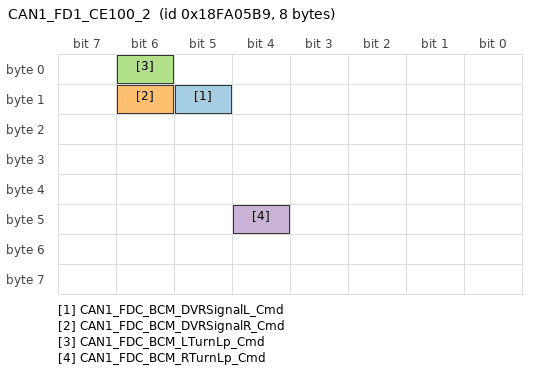
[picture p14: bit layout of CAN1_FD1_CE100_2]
      frame CAN1_FD1_CE100_2: id 0x18FA05B9, frame-length=8, can-addressing-mode=EXTENDED, can-fd-frame-support=false, can-frame-rx-behavior=CAN-20, can-frame-tx-behavior=CAN-20
        pdu CAN1_FD1_CE100_2: length=8, minimum-delay=0.0, transmission-mode-true-timing={cyclic-timing=time-period=0.1, event-controlled-timing={number-of-repetitions=0, repetition-period=0}}, unused-bit-pattern=0
          mapping CAN1_SG_FD1_CE100_2: i-signal-group=CAN1_SG_FD1_CE100_2, start-position=0, transfer-property=TRIGGERED-ON-CHANGE
          signal CAN1_FDC_BCM_DVRSignalL_Cmd: start 13, 1 bit, little-endian, i-signal-type=PRIMITIVE, init-value=constant-reference=Init_CAN1_FDC_BCM_DVRSignalL_Cmd, base-type=uint8, implementation-data-type=uint8, transfer-property=TRIGGERED-ON-CHANGE
          signal CAN1_FDC_BCM_DVRSignalR_Cmd: start 14, 1 bit, little-endian, i-signal-type=PRIMITIVE, init-value=constant-reference=Init_CAN1_FDC_BCM_DVRSignalR_Cmd, base-type=uint8, implementation-data-type=uint8, transfer-property=TRIGGERED-ON-CHANGE
          signal CAN1_FDC_BCM_LTurnLp_Cmd: start 6, 1 bit, little-endian, i-signal-type=PRIMITIVE, init-value=constant-reference=Init_CAN1_FDC_BCM_LTurnLp_Cmd, base-type=uint8, implementation-data-type=uint8, transfer-property=TRIGGERED-ON-CHANGE
          signal CAN1_FDC_BCM_RTurnLp_Cmd: start 44, 1 bit, little-endian, i-signal-type=PRIMITIVE, init-value=constant-reference=Init_CAN1_FDC_BCM_RTurnLp_Cmd, base-type=uint8, implementation-data-type=uint8, transfer-property=TRIGGERED-ON-CHANGE
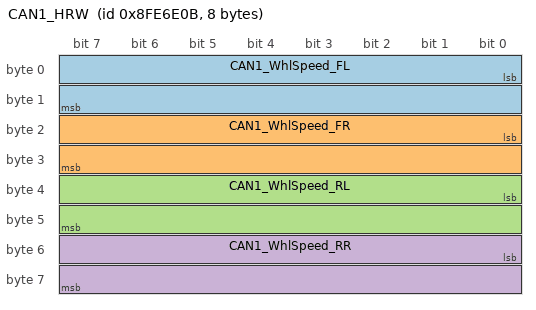
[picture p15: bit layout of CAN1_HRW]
      frame CAN1_HRW: id 0x8FE6E0B, frame-length=8, can-addressing-mode=EXTENDED, can-fd-frame-support=false, can-frame-rx-behavior=CAN-20, can-frame-tx-behavior=CAN-20
        pdu CAN1_HRW: length=8, minimum-delay=0.0, transmission-mode-true-timing=cyclic-timing=time-period=0.02, unused-bit-pattern=0
          mapping CAN1_SG_HRW: i-signal-group=CAN1_SG_HRW, start-position=0, transfer-property=PENDING
          signal CAN1_WhlSpeed_FL: start 0, 16 bit, little-endian, i-signal-type=PRIMITIVE, init-value=constant-reference=Init_CAN1_WhlSpeed_FL, base-type=uint16, implementation-data-type=uint16, transfer-property=PENDING
          signal CAN1_WhlSpeed_FR: start 16, 16 bit, little-endian, i-signal-type=PRIMITIVE, init-value=constant-reference=Init_CAN1_WhlSpeed_FR, base-type=uint16, implementation-data-type=uint16, transfer-property=PENDING
          signal CAN1_WhlSpeed_RL: start 32, 16 bit, little-endian, i-signal-type=PRIMITIVE, init-value=constant-reference=Init_CAN1_WhlSpeed_RL, base-type=uint16, implementation-data-type=uint16, transfer-property=PENDING
          signal CAN1_WhlSpeed_RR: start 48, 16 bit, little-endian, i-signal-type=PRIMITIVE, init-value=constant-reference=Init_CAN1_WhlSpeed_RR, base-type=uint16, implementation-data-type=uint16, transfer-property=PENDING
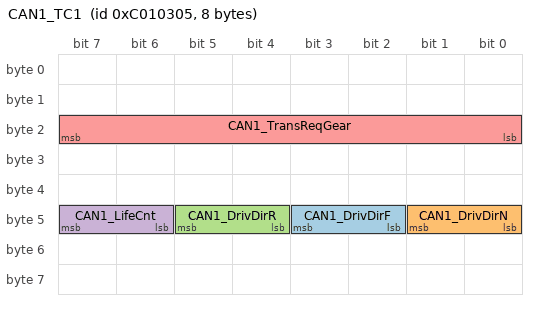
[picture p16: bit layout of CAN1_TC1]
      frame CAN1_TC1: id 0xC010305, frame-length=8, can-addressing-mode=EXTENDED, can-fd-frame-support=false, can-frame-rx-behavior=CAN-20, can-frame-tx-behavior=CAN-20
        pdu CAN1_TC1: length=8, minimum-delay=0.0, transmission-mode-true-timing=cyclic-timing=time-period=0.05, unused-bit-pattern=0
          mapping CAN1_SG_TC1: i-signal-group=CAN1_SG_TC1, start-position=0, transfer-property=PENDING
          signal CAN1_DrivDirF: start 42, 2 bit, little-endian, i-signal-type=PRIMITIVE, init-value=constant-reference=Init_CAN1_DrivDirF, base-type=uint8, implementation-data-type=uint8, transfer-property=PENDING
          signal CAN1_DrivDirN: start 40, 2 bit, little-endian, i-signal-type=PRIMITIVE, init-value=constant-reference=Init_CAN1_DrivDirN, base-type=uint8, implementation-data-type=uint8, transfer-property=PENDING
          signal CAN1_DrivDirR: start 44, 2 bit, little-endian, i-signal-type=PRIMITIVE, init-value=constant-reference=Init_CAN1_DrivDirR, base-type=uint8, implementation-data-type=uint8, transfer-property=PENDING
          signal CAN1_LifeCnt: start 46, 2 bit, little-endian, i-signal-type=PRIMITIVE, init-value=constant-reference=Init_CAN1_LifeCnt, base-type=uint8, implementation-data-type=uint8, transfer-property=PENDING
          signal CAN1_TransReqGear: start 16, 8 bit, little-endian, i-signal-type=PRIMITIVE, init-value=constant-reference=Init_CAN1_TransReqGear, base-type=uint8, implementation-data-type=uint8, transfer-property=PENDING
      frame CAN1_TPMS1: id 0x18F21033, frame-length=8, can-addressing-mode=EXTENDED, can-fd-frame-support=false, can-frame-rx-behavior=CAN-20, can-frame-tx-behavior=CAN-20
        pdu CAN1_TPMS1: length=8, minimum-delay=0.0, transmission-mode-true-timing=cyclic-timing=time-period=1, unused-bit-pattern=0
          mapping CAN1_SG_TPMS1: i-signal-group=CAN1_SG_TPMS1, start-position=0, transfer-property=PENDING
          signal CAN1_LBIBatWarn: start 29, 1 bit, little-endian, i-signal-type=PRIMITIVE, init-value=constant-reference=Init_CAN1_LBIBatWarn, base-type=uint8, implementation-data-type=uint8, transfer-property=PENDING
          signal CAN1_LBIPressIndi: start 10, 2 bit, little-endian, i-signal-type=PRIMITIVE, init-value=constant-reference=Init_CAN1_LBIPressIndi, base-type=uint8, implementation-data-type=uint8, transfer-property=PENDING
          signal CAN1_LBISensorFail: start 23, 1 bit, little-endian, i-signal-type=PRIMITIVE, init-value=constant-reference=Init_CAN1_LBISensorFail, base-type=uint8, implementation-data-type=uint8, transfer-property=PENDING
          signal CAN1_LBIWheelTmpIndi: start 17, 1 bit, little-endian, i-signal-type=PRIMITIVE, init-value=constant-reference=Init_CAN1_LBIWheelTmpIndi, base-type=uint8, implementation-data-type=uint8, transfer-property=PENDING
          signal CAN1_LBOBatWarn: start 27, 1 bit, little-endian, i-signal-type=PRIMITIVE, init-value=constant-reference=Init_CAN1_LBOBatWarn, base-type=uint8, implementation-data-type=uint8, transfer-property=PENDING
          signal CAN1_LBOPressIndi: start 6, 2 bit, little-endian, i-signal-type=PRIMITIVE, init-value=constant-reference=Init_CAN1_LBOPressIndi, base-type=uint8, implementation-data-type=uint8, transfer-property=PENDING
          signal CAN1_LBOSensorFail: start 21, 1 bit, little-endian, i-signal-type=PRIMITIVE, init-value=constant-reference=Init_CAN1_LBOSensorFail, base-type=uint8, implementation-data-type=uint8, transfer-property=PENDING
          signal CAN1_LBOWheelTmpIndi: start 15, 1 bit, little-endian, i-signal-type=PRIMITIVE, init-value=constant-reference=Init_CAN1_LBOWheelTmpIndi, base-type=uint8, implementation-data-type=uint8, transfer-property=PENDING
          signal CAN1_LFBatWarn: start 25, 1 bit, little-endian, i-signal-type=PRIMITIVE, init-value=constant-reference=Init_CAN1_LFBatWarn, base-type=uint8, implementation-data-type=uint8, transfer-property=PENDING
          signal CAN1_LFPressIndi: start 2, 2 bit, little-endian, i-signal-type=PRIMITIVE, init-value=constant-reference=Init_CAN1_LFPressIndi, base-type=uint8, implementation-data-type=uint8, transfer-property=PENDING
          signal CAN1_LFSensorFail: start 19, 1 bit, little-endian, i-signal-type=PRIMITIVE, init-value=constant-reference=Init_CAN1_LFSensorFail, base-type=uint8, implementation-data-type=uint8, transfer-property=PENDING
          signal CAN1_LFWheelTmpIndi: start 13, 1 bit, little-endian, i-signal-type=PRIMITIVE, init-value=constant-reference=Init_CAN1_LFWheelTmpIndi, base-type=uint8, implementation-data-type=uint8, transfer-property=PENDING
          signal CAN1_RBIBatWarn: start 28, 1 bit, little-endian, i-signal-type=PRIMITIVE, init-value=constant-reference=Init_CAN1_RBIBatWarn, base-type=uint8, implementation-data-type=uint8, transfer-property=PENDING
          signal CAN1_RBIPressIndi: start 8, 2 bit, little-endian, i-signal-type=PRIMITIVE, init-value=constant-reference=Init_CAN1_RBIPressIndi, base-type=uint8, implementation-data-type=uint8, transfer-property=PENDING
          signal CAN1_RBISensorFail: start 22, 1 bit, little-endian, i-signal-type=PRIMITIVE, init-value=constant-reference=Init_CAN1_RBISensorFail, base-type=uint8, implementation-data-type=uint8, transfer-property=PENDING
          signal CAN1_RBIWheelTmpIndi: start 16, 1 bit, little-endian, i-signal-type=PRIMITIVE, init-value=constant-reference=Init_CAN1_RBIWheelTmpIndi, base-type=uint8, implementation-data-type=uint8, transfer-property=PENDING
          signal CAN1_RBOBatWarn: start 26, 1 bit, little-endian, i-signal-type=PRIMITIVE, init-value=constant-reference=Init_CAN1_RBOBatWarn, base-type=uint8, implementation-data-type=uint8, transfer-property=PENDING
          signal CAN1_RBOPressIndi: start 4, 2 bit, little-endian, i-signal-type=PRIMITIVE, init-value=constant-reference=Init_CAN1_RBOPressIndi, base-type=uint8, implementation-data-type=uint8, transfer-property=PENDING
          signal CAN1_RBOSensorFail: start 20, 1 bit, little-endian, i-signal-type=PRIMITIVE, init-value=constant-reference=Init_CAN1_RBOSensorFail, base-type=uint8, implementation-data-type=uint8, transfer-property=PENDING
          signal CAN1_RBOWheelTmpIndi: start 14, 1 bit, little-endian, i-signal-type=PRIMITIVE, init-value=constant-reference=Init_CAN1_RBOWheelTmpIndi, base-type=uint8, implementation-data-type=uint8, transfer-property=PENDING
          signal CAN1_RFBatWarn: start 24, 1 bit, little-endian, i-signal-type=PRIMITIVE, init-value=constant-reference=Init_CAN1_RFBatWarn, base-type=uint8, implementation-data-type=uint8, transfer-property=PENDING
          signal CAN1_RFPressIndi: start 0, 2 bit, little-endian, i-signal-type=PRIMITIVE, init-value=constant-reference=Init_CAN1_RFPressIndi, base-type=uint8, implementation-data-type=uint8, transfer-property=PENDING
          signal CAN1_RFSensorFail: start 18, 1 bit, little-endian, i-signal-type=PRIMITIVE, init-value=constant-reference=Init_CAN1_RFSensorFail, base-type=uint8, implementation-data-type=uint8, transfer-property=PENDING
          signal CAN1_RFWheelTmpIndi: start 12, 1 bit, little-endian, i-signal-type=PRIMITIVE, init-value=constant-reference=Init_CAN1_RFWheelTmpIndi, base-type=uint8, implementation-data-type=uint8, transfer-property=PENDING
          signal CAN1_TPMSWarnIndi: start 31, 2 bit, little-endian, i-signal-type=PRIMITIVE, init-value=constant-reference=Init_CAN1_TPMSWarnIndi, base-type=uint8, implementation-data-type=uint8, transfer-property=PENDING
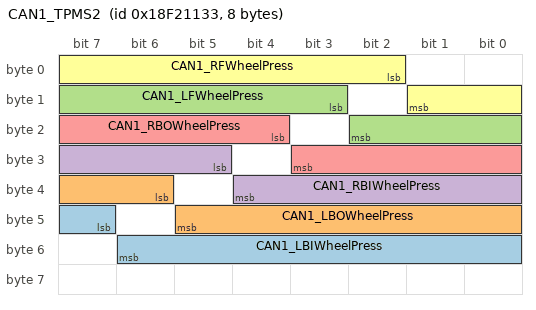
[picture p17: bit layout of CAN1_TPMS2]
      frame CAN1_TPMS2: id 0x18F21133, frame-length=8, can-addressing-mode=EXTENDED, can-fd-frame-support=false, can-frame-rx-behavior=CAN-20, can-frame-tx-behavior=CAN-20
        pdu CAN1_TPMS2: length=8, minimum-delay=0.0, transmission-mode-true-timing=cyclic-timing=time-period=1, unused-bit-pattern=0
          mapping CAN1_SG_TPMS2: i-signal-group=CAN1_SG_TPMS2, start-position=0, transfer-property=PENDING
          signal CAN1_LBIWheelPress: start 47, 8 bit, little-endian, i-signal-type=PRIMITIVE, init-value=constant-reference=Init_CAN1_LBIWheelPress, base-type=uint8, implementation-data-type=uint8, transfer-property=PENDING
          signal CAN1_LBOWheelPress: start 38, 8 bit, little-endian, i-signal-type=PRIMITIVE, init-value=constant-reference=Init_CAN1_LBOWheelPress, base-type=uint8, implementation-data-type=uint8, transfer-property=PENDING
          signal CAN1_LFWheelPress: start 11, 8 bit, little-endian, i-signal-type=PRIMITIVE, init-value=constant-reference=Init_CAN1_LFWheelPress, base-type=uint8, implementation-data-type=uint8, transfer-property=PENDING
          signal CAN1_RBIWheelPress: start 29, 8 bit, little-endian, i-signal-type=PRIMITIVE, init-value=constant-reference=Init_CAN1_RBIWheelPress, base-type=uint8, implementation-data-type=uint8, transfer-property=PENDING
          signal CAN1_RBOWheelPress: start 20, 8 bit, little-endian, i-signal-type=PRIMITIVE, init-value=constant-reference=Init_CAN1_RBOWheelPress, base-type=uint8, implementation-data-type=uint8, transfer-property=PENDING
          signal CAN1_RFWheelPress: start 2, 8 bit, little-endian, i-signal-type=PRIMITIVE, init-value=constant-reference=Init_CAN1_RFWheelPress, base-type=uint8, implementation-data-type=uint8, transfer-property=PENDING
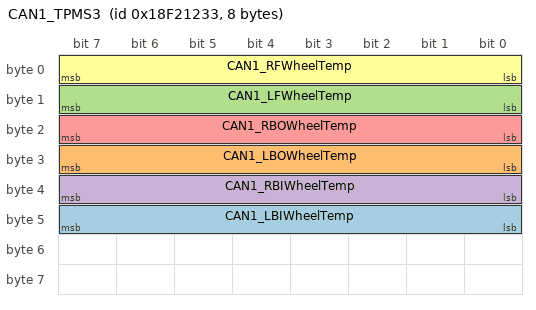
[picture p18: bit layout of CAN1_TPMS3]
      frame CAN1_TPMS3: id 0x18F21233, frame-length=8, can-addressing-mode=EXTENDED, can-fd-frame-support=false, can-frame-rx-behavior=CAN-20, can-frame-tx-behavior=CAN-20
        pdu CAN1_TPMS3: length=8, minimum-delay=0.0, transmission-mode-true-timing=cyclic-timing=time-period=1, unused-bit-pattern=0
          mapping CAN1_SG_TPMS3: i-signal-group=CAN1_SG_TPMS3, start-position=0, transfer-property=PENDING
          signal CAN1_LBIWheelTemp: start 40, 8 bit, little-endian, i-signal-type=PRIMITIVE, init-value=constant-reference=Init_CAN1_LBIWheelTemp, base-type=uint8, implementation-data-type=uint8, transfer-property=PENDING
          signal CAN1_LBOWheelTemp: start 24, 8 bit, little-endian, i-signal-type=PRIMITIVE, init-value=constant-reference=Init_CAN1_LBOWheelTemp, base-type=uint8, implementation-data-type=uint8, transfer-property=PENDING
          signal CAN1_LFWheelTemp: start 8, 8 bit, little-endian, i-signal-type=PRIMITIVE, init-value=constant-reference=Init_CAN1_LFWheelTemp, base-type=uint8, implementation-data-type=uint8, transfer-property=PENDING
          signal CAN1_RBIWheelTemp: start 32, 8 bit, little-endian, i-signal-type=PRIMITIVE, init-value=constant-reference=Init_CAN1_RBIWheelTemp, base-type=uint8, implementation-data-type=uint8, transfer-property=PENDING
          signal CAN1_RBOWheelTemp: start 16, 8 bit, little-endian, i-signal-type=PRIMITIVE, init-value=constant-reference=Init_CAN1_RBOWheelTemp, base-type=uint8, implementation-data-type=uint8, transfer-property=PENDING
          signal CAN1_RFWheelTemp: start 0, 8 bit, little-endian, i-signal-type=PRIMITIVE, init-value=constant-reference=Init_CAN1_RFWheelTemp, base-type=uint8, implementation-data-type=uint8, transfer-property=PENDING
      frame CAN1_VDC1: id 0x18FE4F0B, frame-length=8, can-addressing-mode=EXTENDED, can-fd-frame-support=false, can-frame-rx-behavior=CAN-20, can-frame-tx-behavior=CAN-20
        pdu CAN1_VDC1: length=8, minimum-delay=0.0, transmission-mode-true-timing=cyclic-timing=time-period=0.1, unused-bit-pattern=0
          mapping CAN1_SG_VDC1: i-signal-group=CAN1_SG_VDC1, start-position=0, transfer-property=PENDING
          signal CAN1_VDCBrakeLightReq: start 4, 2 bit, little-endian, i-signal-type=PRIMITIVE, init-value=constant-reference=Init_CAN1_VDCBrakeLightReq, base-type=uint8, implementation-data-type=uint8, transfer-property=PENDING
      frame CAN1_NMm_FUSION_TX: id 0x500, frame-length=8, can-addressing-mode=STANDARD, can-fd-frame-support=false, can-frame-rx-behavior=CAN-20, can-frame-tx-behavior=CAN-20
        nm pdu CAN1_NMm_FUSION_TX: length=8, unused-bit-pattern=0
      frame CAN1_NMm_FUSION_RX: id 0x500, frame-length=8, can-addressing-mode=STANDARD, can-fd-frame-support=false, can-frame-rx-behavior=CAN-20, can-frame-tx-behavior=CAN-20
        nm pdu CAN1_NMm_FUSION_RX: length=8, unused-bit-pattern=0
package /CAN1/ConstantSpecification
  263 x constant specification:
    Init_CAN1_ACAmbTemp: value-spec=0
    Init_CAN1_ACCabinTemp: value-spec=0
    Init_CAN1_THCM_Reserve{1..4}_Sta: value-spec=0
    Init_CAN1_ACFanSpdSta: value-spec=0
    Init_CAN1_ACMODESta: value-spec=0
    Init_CAN1_ACPwrSta: value-spec=0
    Init_CAN1_THCM_Outcycle_Sta: value-spec=0
    Init_CAN1_THCM_Reserve{10..13}_Sta: value-spec=0
    Init_CAN1_THCM_Reserve{5..9}_Sta: value-spec=0
    Init_CAN1_THCM_Faultlv_Sta: value-spec=0
    Init_CAN1_TM2BFaultCode: value-spec=0
    Init_CAN1_TM2BFaultLv: value-spec=0
    Init_CAN1_TM2BInletTemp: value-spec=0
    Init_CAN1_TM2BOutletTemp: value-spec=0
    Init_CAN1_TM2BRQPower: value-spec=0
    Init_CAN1_TM2BTMSHVRlySta: value-spec=0
    Init_CAN1_TM2BWorkStatus: value-spec=0
    Init_CAN1_ACTempSetSta: value-spec=0
    Init_CAN1_ASC1KneelingInfo: value-spec=0
    Init_CAN1_ABSFullyOper: value-spec=0
    Init_CAN1_ABSOffroadSw: value-spec=0
    Init_CAN1_ASRBrakeCtrlAtc: value-spec=0
    Init_CAN1_ASREngCtrlAtc: value-spec=0
    Init_CAN1_ASRHillHolderSw: value-spec=0
    Init_CAN1_ASROffroadSw: value-spec=0
    Init_CAN1_ATCASRInfoSig: value-spec=0
    Init_CAN1_AcltrInterlockSw: value-spec=0
    Init_CAN1_AntiLBrakABSAct: value-spec=0
    Init_CAN1_BrakePedalPos: value-spec=0
    Init_CAN1_EBSAmWarnLampSta: value-spec=0
    Init_CAN1_EBSBrakeSw: value-spec=0
    Init_CAN1_EBSRedWarnLampSta: value-spec=0
    Init_CAN1_EngAuxShutdownSw: value-spec=0
    Init_CAN1_EngDerateSw: value-spec=0
    Init_CAN1_EngRetSel: value-spec=0
    Init_CAN1_HaltBrakeSw: value-spec=0
    Init_CAN1_RmAccelEnSw: value-spec=0
    Init_CAN1_SACtrlBrakeCtrl: value-spec=0
    Init_CAN1_TractCtrlOvrSw: value-spec=0
    Init_CAN1_TrailerABSSta: value-spec=0
    Init_CAN1_TrailerABSWarnSig: value-spec=0
    Init_CAN1_FASpeed: value-spec=0
    Init_CAN1_RelaSpdFALWheel: value-spec=0
    Init_CAN1_RelaSpdFARWheel: value-spec=0
    Init_CAN1_RelaSpdRA1LWheel: value-spec=0
    Init_CAN1_RelaSpdRA1RWheel: value-spec=0
    Init_CAN1_RelaSpdRA2LWheel: value-spec=0
    Init_CAN1_RelaSpdRA2RWheel: value-spec=0
    Init_CAN1_BrkTempeWarn: value-spec=0
    Init_CAN1_EmhBrkAct: value-spec=0
    Init_CAN1_FndBrkUse: value-spec=0
    Init_CAN1_HaltBrkMode: value-spec=0
    Init_CAN1_HillHolderMode: value-spec=0
    Init_CAN1_ParkBrkActuFAct: value-spec=0
    Init_CAN1_RailroadMode: value-spec=0
    Init_CAN1_XBRAcltnLimit: value-spec=0
    Init_CAN1_XBRActtrlMode: value-spec=0
    Init_CAN1_XBRSysSta: value-spec=0
    Init_CAN1_ECASAWarmLampSta: value-spec=0
    Init_CAN1_EM1CS: value-spec=0
    Init_CAN1_EM1Cnt: value-spec=0
    Init_CAN1_EM1OvrCtrlMBrk: value-spec=0
    Init_CAN1_EM1OvrCtrlMDriv: value-spec=0
    Init_CAN1_EM1OvrCtrlMPriBrk: value-spec=0
    Init_CAN1_EM1OvrCtrlMPriDriv: value-spec=0
    Init_CAN1_EM1ReqTorqHRlsBrk: value-spec=0
    Init_CAN1_EM1ReqTorqHRlsDri: value-spec=0
    Init_CAN1_EM1ReqTorqLimBrk: value-spec=0
    Init_CAN1_EM1ReqTorqLimDriv: value-spec=0
    Init_CAN1_AirPressureFC2: value-spec=0
    Init_CAN1_AirPressurePC3: value-spec=0
    Init_CAN1_AirPressureRC1: value-spec=0
    Init_CAN1_VCUEBSRd4BR: value-spec=0
    Init_CAN1_VCUEBSHBSw: value-spec=0
    Init_CAN1_VCUEBSHHSw: value-spec=0
    Init_CAN1_GearFlashInd: value-spec=0
    Init_CAN1_LVBattLow: value-spec=0
    Init_CAN1_PweLmtInd: value-spec=0
    Init_CAN1_VCUBCMBuzzReq: value-spec=0
    Init_CAN1_VCUDTCCurrCode: value-spec=0
    Init_CAN1_VCUDTCCurrSta: value-spec=0
    Init_CAN1_VCUDTCHisCode: value-spec=0
    Init_CAN1_VCUDTCHisSta: value-spec=0
    Init_CAN1_VCUKeyStatus: value-spec=0
    Init_CAN1_VCUWarnInd: value-spec=0
    Init_CAN1_VCUnoPBInd: value-spec=0
    Init_CAN1_BrakeSW: value-spec=0
    Init_CAN1_ParkBrakeSW: value-spec=0
    Init_CAN1_VCUVehSpd: value-spec=0
    Init_CAN1_VehActDriveDirect: value-spec=0
    Init_CAN1_ActEMOutSftSpd: value-spec=0
    Init_CAN1_ActEMpTrq: value-spec=0
    Init_CAN1_ActEMpTrqHrls: value-spec=0
    Init_CAN1_ActMaxAvaEMRecpTrq: value-spec=125
    Init_CAN1_DrvDemEMRtapTrq: value-spec=125
    Init_CAN1_EMTrqModeDrvBrk: value-spec=0
    Init_CAN1_RetSelNonEng: value-spec=125
    Init_CAN1_SACtrlDev: value-spec=0
    Init_CAN1_SysPowerMode: value-spec=0
    Init_CAN1_DCCurr: value-spec=32768
    Init_CAN1_DCVol: value-spec=0
    Init_CAN1_MaxTorqAvail: value-spec=125
    Init_CAN1_MinTorqAvail: value-spec=125
    Init_CAN1_EMParasLoss: value-spec=125
    Init_CAN1_NFricPercTorq: value-spec=125
    Init_CAN1_RC1MaxRetSpdP2: value-spec=0
    Init_CAN1_RC1PctTrqIdleP1: value-spec=0
    Init_CAN1_RC1PctTrqMaxSpdP2: value-spec=0
    Init_CAN1_RC1PctTrqP3: value-spec=0
    Init_CAN1_RC1PctTrqP4: value-spec=0
    Init_CAN1_RC1PctTrqPekTrqP5: value-spec=0
    Init_CAN1_RC1RefRetTrq: value-spec=0
    Init_CAN1_RC1RetCtrlMth: value-spec=0
    Init_CAN1_RC1RetLocat: value-spec=0
    Init_CAN1_RC1RetSpdIdleP1: value-spec=0
    Init_CAN1_RC1RetSpdP3: value-spec=0
    Init_CAN1_RC1RetSpdP4: value-spec=0
    Init_CAN1_RC1RetSpdPekTrqP5: value-spec=0
    Init_CAN1_RC1RetType: value-spec=0
    Init_CAN1_EMDefTrqLmt: value-spec=0
    Init_CAN1_EMEMRefTorq: value-spec=0
    Init_CAN1_EMEMSpdP{2..5}: value-spec=0
    Init_CAN1_EMExtRSCtrlUpLmt: value-spec=0
    Init_CAN1_EMGainEndSpdGvn: value-spec=0
    Init_CAN1_EMMaxMEngOvrSP7: value-spec=0
    Init_CAN1_EMMaxMOvrTLmt: value-spec=0
    Init_CAN1_EMMomOfInertia: value-spec=0
    Init_CAN1_EMPercTorqIdleP1: value-spec=0
    Init_CAN1_EMPercTorqP{2..5}: value-spec=0
    Init_CAN1_EMReqSpdCtrlLoLmt: value-spec=0
    Init_CAN1_EMReqSpdCtrlUpLmt: value-spec=0
    Init_CAN1_EMReqTrqCtrlLoLmt: value-spec=0
    Init_CAN1_EMReqTrqCtrlUpLmt: value-spec=0
    Init_CAN1_EMSpdHIdleP6: value-spec=0
    Init_CAN1_EMSpdIdleP1: value-spec=0
    Init_CAN1_EMSupTSC1CtrlPG{1..4}: value-spec=0
    Init_CAN1_EMSupVarRTSC1MSG: value-spec=0
    Init_CAN1_ActDriveDirect: value-spec=0
    Init_CAN1_AccPedal1LowSW: value-spec=0
    Init_CAN1_AccPedalPos1: value-spec=0
    Init_CAN1_EEC2MSGCS: value-spec=0
    Init_CAN1_EEC2MSGCnt: value-spec=0
    Init_CAN1_DLEngaged: value-spec=0
    Init_CAN1_ShiftPgs: value-spec=0
    Init_CAN1_CFGEM1DT{0..7}: value-spec=0
    Init_CAN1_CFGEM1BAMPGN: value-spec=0
    Init_CAN1_CFGEM1BAMRsv: value-spec=0
    Init_CAN1_CFGEM1BAMTNum: value-spec=0
    Init_CAN1_CFGEM1BAMTSize: value-spec=0
    Init_CAN1_CFGEM1Ctrl: value-spec=0
    Init_CAN1_FDC_BCM_DVRSignalL_Cmd: value-spec=0
    Init_CAN1_FDC_BCM_DVRSignalR_Cmd: value-spec=0
    Init_CAN1_FDC_BCM_LTurnLp_Cmd: value-spec=0
    Init_CAN1_FDC_BCM_RTurnLp_Cmd: value-spec=0
    Init_CAN1_WhlSpeed_FL: value-spec=0
    Init_CAN1_WhlSpeed_FR: value-spec=0
    Init_CAN1_WhlSpeed_RL: value-spec=0
    Init_CAN1_WhlSpeed_RR: value-spec=0
    Init_CAN1_DrivDirF: value-spec=0
    Init_CAN1_DrivDirN: value-spec=0
    Init_CAN1_DrivDirR: value-spec=0
    Init_CAN1_LifeCnt: value-spec=0
    Init_CAN1_TransReqGear: value-spec=0
    Init_CAN1_LBIBatWarn: value-spec=0
    Init_CAN1_LBIPressIndi: value-spec=0
    Init_CAN1_LBISensorFail: value-spec=0
    Init_CAN1_LBIWheelTmpIndi: value-spec=0
    Init_CAN1_LBOBatWarn: value-spec=0
    Init_CAN1_LBOPressIndi: value-spec=0
    Init_CAN1_LBOSensorFail: value-spec=0
    Init_CAN1_LBOWheelTmpIndi: value-spec=0
    Init_CAN1_LFBatWarn: value-spec=0
    Init_CAN1_LFPressIndi: value-spec=0
    Init_CAN1_LFSensorFail: value-spec=0
    Init_CAN1_LFWheelTmpIndi: value-spec=0
    Init_CAN1_RBIBatWarn: value-spec=0
    Init_CAN1_RBIPressIndi: value-spec=0
    Init_CAN1_RBISensorFail: value-spec=0
    Init_CAN1_RBIWheelTmpIndi: value-spec=0
    Init_CAN1_RBOBatWarn: value-spec=0
    Init_CAN1_RBOPressIndi: value-spec=0
    Init_CAN1_RBOSensorFail: value-spec=0
    Init_CAN1_RBOWheelTmpIndi: value-spec=0
    Init_CAN1_RFBatWarn: value-spec=0
    Init_CAN1_RFPressIndi: value-spec=0
    Init_CAN1_RFSensorFail: value-spec=0
    Init_CAN1_RFWheelTmpIndi: value-spec=0
    Init_CAN1_TPMSWarnIndi: value-spec=0
    Init_CAN1_LBIWheelPress: value-spec=0
    Init_CAN1_LBOWheelPress: value-spec=0
    Init_CAN1_LFWheelPress: value-spec=0
    Init_CAN1_RBIWheelPress: value-spec=0
    Init_CAN1_RBOWheelPress: value-spec=0
    Init_CAN1_RFWheelPress: value-spec=0
    Init_CAN1_LBIWheelTemp: value-spec=0
    Init_CAN1_LBOWheelTemp: value-spec=0
    Init_CAN1_LFWheelTemp: value-spec=0
    Init_CAN1_RBIWheelTemp: value-spec=0
    Init_CAN1_RBOWheelTemp: value-spec=0
    Init_CAN1_RFWheelTemp: value-spec=0
    Init_CAN1_VDCBrakeLightReq: value-spec=0
    Init_CAN1_SG_AC_BTMS_C1000_0: value-spec=fields=[Init_CAN1_ACAmbTemp, Init_CAN1_ACCabinTemp, Init_CAN1_THCM_Reserve1_Sta, Init_CAN1_THCM_Reserve2_Sta, Init_CAN1_THCM_Reserve3_Sta, Init_CAN1_THCM_Reserve4_Sta]
    Init_CAN1_SG_AC_BTMS_C1000_1: value-spec=fields=[Init_CAN1_ACFanSpdSta, Init_CAN1_ACMODESta, Init_CAN1_ACPwrSta, Init_CAN1_THCM_Outcycle_Sta, Init_CAN1_THCM_Reserve10_Sta, Init_CAN1_THCM_Reserve11_Sta, Init_CAN1_THCM_Reserve12_Sta, Init_CAN1_THCM_Reserve13_Sta, Init_CAN1_THCM_Reserve5_Sta, Init_CAN1_THCM_Reserve6_Sta, Init_CAN1_THCM_Reserve7_Sta, Init_CAN1_THCM_Reserve8_Sta, Init_CAN1_THCM_Reserve9_Sta]
    Init_CAN1_SG_AC_BTMS_C1000_2: value-spec=fields=constant-reference=Init_CAN1_THCM_Faultlv_Sta
    Init_CAN1_SG_AC_BTMS_C1000_4: value-spec=fields=[Init_CAN1_TM2BFaultCode, Init_CAN1_TM2BFaultLv, Init_CAN1_TM2BInletTemp, Init_CAN1_TM2BOutletTemp, Init_CAN1_TM2BRQPower, Init_CAN1_TM2BTMSHVRlySta, Init_CAN1_TM2BWorkStatus]
    Init_CAN1_SG_AC_BTMS_C5000_0: value-spec=fields=constant-reference=Init_CAN1_ACTempSetSta
    Init_CAN1_SG_ASC1_A: value-spec=fields=constant-reference=Init_CAN1_ASC1KneelingInfo
    Init_CAN1_SG_EBC1: value-spec=fields=[Init_CAN1_ABSFullyOper, Init_CAN1_ABSOffroadSw, Init_CAN1_ASRBrakeCtrlAtc, Init_CAN1_ASREngCtrlAtc, Init_CAN1_ASRHillHolderSw, Init_CAN1_ASROffroadSw, Init_CAN1_ATCASRInfoSig, Init_CAN1_AcltrInterlockSw, Init_CAN1_AntiLBrakABSAct, Init_CAN1_BrakePedalPos, Init_CAN1_EBSAmWarnLampSta, Init_CAN1_EBSBrakeSw, Init_CAN1_EBSRedWarnLampSta, Init_CAN1_EngAuxShutdownSw, Init_CAN1_EngDerateSw, Init_CAN1_EngRetSel, Init_CAN1_HaltBrakeSw, Init_CAN1_RmAccelEnSw, Init_CAN1_SACtrlBrakeCtrl, Init_CAN1_TractCtrlOvrSw, Init_CAN1_TrailerABSSta, Init_CAN1_TrailerABSWarnSig]
    Init_CAN1_SG_EBC2: value-spec=fields=[Init_CAN1_FASpeed, Init_CAN1_RelaSpdFALWheel, Init_CAN1_RelaSpdFARWheel, Init_CAN1_RelaSpdRA1LWheel, Init_CAN1_RelaSpdRA1RWheel, Init_CAN1_RelaSpdRA2LWheel, Init_CAN1_RelaSpdRA2RWheel]
    Init_CAN1_SG_EBC5: value-spec=fields=[Init_CAN1_BrkTempeWarn, Init_CAN1_EmhBrkAct, Init_CAN1_FndBrkUse, Init_CAN1_HaltBrkMode, Init_CAN1_HillHolderMode, Init_CAN1_ParkBrkActuFAct, Init_CAN1_RailroadMode, Init_CAN1_XBRAcltnLimit, Init_CAN1_XBRActtrlMode, Init_CAN1_XBRSysSta]
    Init_CAN1_SG_ECAS_DM1: value-spec=fields=constant-reference=Init_CAN1_ECASAWarmLampSta
    Init_CAN1_SG_EMC1_EM1: value-spec=fields=[Init_CAN1_EM1CS, Init_CAN1_EM1Cnt, Init_CAN1_EM1OvrCtrlMBrk, Init_CAN1_EM1OvrCtrlMDriv, Init_CAN1_EM1OvrCtrlMPriBrk, Init_CAN1_EM1OvrCtrlMPriDriv, Init_CAN1_EM1ReqTorqHRlsBrk, Init_CAN1_EM1ReqTorqHRlsDri, Init_CAN1_EM1ReqTorqLimBrk, Init_CAN1_EM1ReqTorqLimDriv]
    Init_CAN1_SG_FD1_C1000_0: value-spec=fields=[Init_CAN1_AirPressureFC2, Init_CAN1_AirPressurePC3, Init_CAN1_AirPressureRC1]
    Init_CAN1_SG_FD1_C100_0: value-spec=fields=constant-reference=Init_CAN1_VCUEBSRd4BR
    Init_CAN1_SG_FD1_C100_1: value-spec=fields=[Init_CAN1_VCUEBSHBSw, Init_CAN1_VCUEBSHHSw]
    Init_CAN1_SG_FD1_C100_2: value-spec=fields=[Init_CAN1_GearFlashInd, Init_CAN1_LVBattLow, Init_CAN1_PweLmtInd, Init_CAN1_VCUBCMBuzzReq, Init_CAN1_VCUDTCCurrCode, Init_CAN1_VCUDTCCurrSta, Init_CAN1_VCUDTCHisCode, Init_CAN1_VCUDTCHisSta, Init_CAN1_VCUKeyStatus, Init_CAN1_VCUWarnInd, Init_CAN1_VCUnoPBInd]
    Init_CAN1_SG_FD1_C100_3: value-spec=fields=[Init_CAN1_BrakeSW, Init_CAN1_VCUVehSpd]
    Init_CAN1_SG_CGW_FD1_C100_3: value-spec=fields=constant-reference=Init_CAN1_ParkBrakeSW
    Init_CAN1_SG_FD1_C10_0: value-spec=fields=constant-reference=Init_CAN1_VehActDriveDirect
    Init_CAN1_SG_FD1_C10_1: value-spec=fields=[Init_CAN1_ActEMOutSftSpd, Init_CAN1_ActEMpTrq, Init_CAN1_ActEMpTrqHrls, Init_CAN1_ActMaxAvaEMRecpTrq, Init_CAN1_DrvDemEMRtapTrq, Init_CAN1_EMTrqModeDrvBrk, Init_CAN1_RetSelNonEng, Init_CAN1_SACtrlDev]
    Init_CAN1_SG_FD1_C200_0: value-spec=fields=constant-reference=Init_CAN1_SysPowerMode
    Init_CAN1_SG_FD1_C20_0: value-spec=fields=[Init_CAN1_DCCurr, Init_CAN1_DCVol, Init_CAN1_MaxTorqAvail, Init_CAN1_MinTorqAvail]
    Init_CAN1_SG_FD1_C250_0: value-spec=fields=[Init_CAN1_EMParasLoss, Init_CAN1_NFricPercTorq]
    Init_CAN1_SG_FD1_C5000_0: value-spec=fields=[Init_CAN1_RC1MaxRetSpdP2, Init_CAN1_RC1PctTrqIdleP1, Init_CAN1_RC1PctTrqMaxSpdP2, Init_CAN1_RC1PctTrqP3, Init_CAN1_RC1PctTrqP4, Init_CAN1_RC1PctTrqPekTrqP5, Init_CAN1_RC1RefRetTrq, Init_CAN1_RC1RetCtrlMth, Init_CAN1_RC1RetLocat, Init_CAN1_RC1RetSpdIdleP1, Init_CAN1_RC1RetSpdP3, Init_CAN1_RC1RetSpdP4, Init_CAN1_RC1RetSpdPekTrqP5, Init_CAN1_RC1RetType]
    Init_CAN1_SG_FD1_C5000_1: value-spec=fields=[Init_CAN1_EMDefTrqLmt, Init_CAN1_EMEMRefTorq, Init_CAN1_EMEMSpdP2, Init_CAN1_EMEMSpdP3, Init_CAN1_EMEMSpdP4, Init_CAN1_EMEMSpdP5, Init_CAN1_EMExtRSCtrlUpLmt, Init_CAN1_EMGainEndSpdGvn, Init_CAN1_EMMaxMEngOvrSP7, Init_CAN1_EMMaxMOvrTLmt, Init_CAN1_EMMomOfInertia, Init_CAN1_EMPercTorqIdleP1, Init_CAN1_EMPercTorqP2, Init_CAN1_EMPercTorqP3, Init_CAN1_EMPercTorqP4, Init_CAN1_EMPercTorqP5, Init_CAN1_EMReqSpdCtrlLoLmt, Init_CAN1_EMReqSpdCtrlUpLmt, Init_CAN1_EMReqTrqCtrlLoLmt, Init_CAN1_EMReqTrqCtrlUpLmt, Init_CAN1_EMSpdHIdleP6, Init_CAN1_EMSpdIdleP1, Init_CAN1_EMSupTSC1CtrlPG1, Init_CAN1_EMSupTSC1CtrlPG2, Init_CAN1_EMSupTSC1CtrlPG3, Init_CAN1_EMSupTSC1CtrlPG4, Init_CAN1_EMSupVarRTSC1MSG]
    Init_CAN1_SG_FD1_C50_0: value-spec=fields=constant-reference=Init_CAN1_ActDriveDirect
    Init_CAN1_SG_FD1_C50_1: value-spec=fields=[Init_CAN1_AccPedal1LowSW, Init_CAN1_AccPedalPos1, Init_CAN1_EEC2MSGCS, Init_CAN1_EEC2MSGCnt]
    Init_CAN1_SG_FD1_C80_0: value-spec=fields=[Init_CAN1_DLEngaged, Init_CAN1_ShiftPgs]
    Init_CAN1_SG_FD1_CE100_0: value-spec=fields=[Init_CAN1_CFGEM1DT0, Init_CAN1_CFGEM1DT1, Init_CAN1_CFGEM1DT2, Init_CAN1_CFGEM1DT3, Init_CAN1_CFGEM1DT4, Init_CAN1_CFGEM1DT5, Init_CAN1_CFGEM1DT6, Init_CAN1_CFGEM1DT7]
    Init_CAN1_SG_FD1_CE100_1: value-spec=fields=[Init_CAN1_CFGEM1BAMPGN, Init_CAN1_CFGEM1BAMRsv, Init_CAN1_CFGEM1BAMTNum, Init_CAN1_CFGEM1BAMTSize, Init_CAN1_CFGEM1Ctrl]
    Init_CAN1_SG_FD1_CE100_2: value-spec=fields=[Init_CAN1_FDC_BCM_DVRSignalL_Cmd, Init_CAN1_FDC_BCM_DVRSignalR_Cmd, Init_CAN1_FDC_BCM_LTurnLp_Cmd, Init_CAN1_FDC_BCM_RTurnLp_Cmd]
    Init_CAN1_SG_HRW: value-spec=fields=[Init_CAN1_WhlSpeed_FL, Init_CAN1_WhlSpeed_FR, Init_CAN1_WhlSpeed_RL, Init_CAN1_WhlSpeed_RR]
    Init_CAN1_SG_TC1: value-spec=fields=[Init_CAN1_DrivDirF, Init_CAN1_DrivDirN, Init_CAN1_DrivDirR, Init_CAN1_LifeCnt, Init_CAN1_TransReqGear]
    Init_CAN1_SG_TPMS1: value-spec=fields=[Init_CAN1_LBIBatWarn, Init_CAN1_LBIPressIndi, Init_CAN1_LBISensorFail, Init_CAN1_LBIWheelTmpIndi, Init_CAN1_LBOBatWarn, Init_CAN1_LBOPressIndi, Init_CAN1_LBOSensorFail, Init_CAN1_LBOWheelTmpIndi, Init_CAN1_LFBatWarn, Init_CAN1_LFPressIndi, Init_CAN1_LFSensorFail, Init_CAN1_LFWheelTmpIndi, Init_CAN1_RBIBatWarn, Init_CAN1_RBIPressIndi, Init_CAN1_RBISensorFail, Init_CAN1_RBIWheelTmpIndi, Init_CAN1_RBOBatWarn, Init_CAN1_RBOPressIndi, Init_CAN1_RBOSensorFail, Init_CAN1_RBOWheelTmpIndi, Init_CAN1_RFBatWarn, Init_CAN1_RFPressIndi, Init_CAN1_RFSensorFail, Init_CAN1_RFWheelTmpIndi, Init_CAN1_TPMSWarnIndi]
    Init_CAN1_SG_TPMS2: value-spec=fields=[Init_CAN1_LBIWheelPress, Init_CAN1_LBOWheelPress, Init_CAN1_LFWheelPress, Init_CAN1_RBIWheelPress, Init_CAN1_RBOWheelPress, Init_CAN1_RFWheelPress]
    Init_CAN1_SG_TPMS3: value-spec=fields=[Init_CAN1_LBIWheelTemp, Init_CAN1_LBOWheelTemp, Init_CAN1_LFWheelTemp, Init_CAN1_RBIWheelTemp, Init_CAN1_RBOWheelTemp, Init_CAN1_RFWheelTemp]
    Init_CAN1_SG_VDC1: value-spec=fields=constant-reference=Init_CAN1_VDCBrakeLightReq
package /CAN1/ImplementationDataTypes
  36 x impl type, all with category=STRUCTURE:
    DT_CAN1_SG_AC_BTMS_C1000_0
      6 x element, all with category=TYPE_REFERENCE:
        CAN1_ACAmbTemp: implementation-data-type=uint16
        CAN1_ACCabinTemp: implementation-data-type=uint16
        CAN1_THCM_Reserve{1..4}_Sta: implementation-data-type=uint8
    DT_CAN1_SG_AC_BTMS_C1000_1
      13 x element, all with category=TYPE_REFERENCE, implementation-data-type=uint8:
        CAN1_ACFanSpdSta
        CAN1_ACMODESta
        CAN1_ACPwrSta
        CAN1_THCM_Outcycle_Sta
        CAN1_THCM_Reserve{10..13}_Sta
        CAN1_THCM_Reserve{5..9}_Sta
    DT_CAN1_SG_AC_BTMS_C1000_2
      element CAN1_THCM_Faultlv_Sta: implementation-data-type=uint8
    DT_CAN1_SG_AC_BTMS_C1000_4
      7 x element, all with category=TYPE_REFERENCE:
        CAN1_TM2BFaultCode: implementation-data-type=uint8
        CAN1_TM2BFaultLv: implementation-data-type=uint8
        CAN1_TM2BInletTemp: implementation-data-type=uint8
        CAN1_TM2BOutletTemp: implementation-data-type=uint8
        CAN1_TM2BRQPower: implementation-data-type=uint16
        CAN1_TM2BTMSHVRlySta: implementation-data-type=uint8
        CAN1_TM2BWorkStatus: implementation-data-type=uint8
    DT_CAN1_SG_AC_BTMS_C5000_0
      element CAN1_ACTempSetSta: implementation-data-type=uint8
    DT_CAN1_SG_ASC1_A
      element CAN1_ASC1KneelingInfo: implementation-data-type=uint8
    DT_CAN1_SG_EBC1
      22 x element, all with category=TYPE_REFERENCE, implementation-data-type=uint8:
        CAN1_ABSFullyOper
        CAN1_ABSOffroadSw
        CAN1_ASRBrakeCtrlAtc
        CAN1_ASREngCtrlAtc
        CAN1_ASRHillHolderSw
        CAN1_ASROffroadSw
        CAN1_ATCASRInfoSig
        CAN1_AcltrInterlockSw
        CAN1_AntiLBrakABSAct
        CAN1_BrakePedalPos
        CAN1_EBSAmWarnLampSta
        CAN1_EBSBrakeSw
        CAN1_EBSRedWarnLampSta
        CAN1_EngAuxShutdownSw
        CAN1_EngDerateSw
        CAN1_EngRetSel
        CAN1_HaltBrakeSw
        CAN1_RmAccelEnSw
        CAN1_SACtrlBrakeCtrl
        CAN1_TractCtrlOvrSw
        CAN1_TrailerABSSta
        CAN1_TrailerABSWarnSig
    DT_CAN1_SG_EBC2
      7 x element, all with category=TYPE_REFERENCE:
        CAN1_FASpeed: implementation-data-type=uint16
        CAN1_RelaSpdFALWheel: implementation-data-type=uint8
        CAN1_RelaSpdFARWheel: implementation-data-type=uint8
        CAN1_RelaSpdRA1LWheel: implementation-data-type=uint8
        CAN1_RelaSpdRA1RWheel: implementation-data-type=uint8
        CAN1_RelaSpdRA2LWheel: implementation-data-type=uint8
        CAN1_RelaSpdRA2RWheel: implementation-data-type=uint8
    DT_CAN1_SG_EBC5
      10 x element, all with category=TYPE_REFERENCE, implementation-data-type=uint8:
        CAN1_BrkTempeWarn
        CAN1_EmhBrkAct
        CAN1_FndBrkUse
        CAN1_HaltBrkMode
        CAN1_HillHolderMode
        CAN1_ParkBrkActuFAct
        CAN1_RailroadMode
        CAN1_XBRAcltnLimit
        CAN1_XBRActtrlMode
        CAN1_XBRSysSta
    DT_CAN1_SG_ECAS_DM1
      element CAN1_ECASAWarmLampSta: implementation-data-type=uint8
    DT_CAN1_SG_EMC1_EM1
      10 x element, all with category=TYPE_REFERENCE, implementation-data-type=uint8:
        CAN1_EM1CS
        CAN1_EM1Cnt
        CAN1_EM1OvrCtrlMBrk
        CAN1_EM1OvrCtrlMDriv
        CAN1_EM1OvrCtrlMPriBrk
        CAN1_EM1OvrCtrlMPriDriv
        CAN1_EM1ReqTorqHRlsBrk
        CAN1_EM1ReqTorqHRlsDri
        CAN1_EM1ReqTorqLimBrk
        CAN1_EM1ReqTorqLimDriv
    DT_CAN1_SG_FD1_C1000_0
      element CAN1_AirPressureFC2: implementation-data-type=uint8
      element CAN1_AirPressurePC3: implementation-data-type=uint8
      element CAN1_AirPressureRC1: implementation-data-type=uint8
    DT_CAN1_SG_FD1_C100_0
      element CAN1_VCUEBSRd4BR: implementation-data-type=uint8
    DT_CAN1_SG_FD1_C100_1
      element CAN1_VCUEBSHBSw: implementation-data-type=uint8
      element CAN1_VCUEBSHHSw: implementation-data-type=uint8
    DT_CAN1_SG_FD1_C100_2
      11 x element, all with category=TYPE_REFERENCE:
        CAN1_GearFlashInd: implementation-data-type=uint8
        CAN1_LVBattLow: implementation-data-type=uint8
        CAN1_PweLmtInd: implementation-data-type=uint8
        CAN1_VCUBCMBuzzReq: implementation-data-type=uint8
        CAN1_VCUDTCCurrCode: implementation-data-type=uint32
        CAN1_VCUDTCCurrSta: implementation-data-type=uint8
        CAN1_VCUDTCHisCode: implementation-data-type=uint32
        CAN1_VCUDTCHisSta: implementation-data-type=uint8
        CAN1_VCUKeyStatus: implementation-data-type=uint8
        CAN1_VCUWarnInd: implementation-data-type=uint8
        CAN1_VCUnoPBInd: implementation-data-type=uint8
    DT_CAN1_SG_FD1_C100_3
      element CAN1_BrakeSW: implementation-data-type=uint8
      element CAN1_VCUVehSpd: implementation-data-type=uint16
    DT_CAN1_SG_CGW_FD1_C100_3
      element CAN1_ParkBrakeSW: implementation-data-type=uint8
    DT_CAN1_SG_FD1_C10_0
      element CAN1_VehActDriveDirect: implementation-data-type=uint8
    DT_CAN1_SG_FD1_C10_1
      8 x element, all with category=TYPE_REFERENCE:
        CAN1_ActEMOutSftSpd: implementation-data-type=uint16
        CAN1_ActEMpTrq: implementation-data-type=uint8
        CAN1_ActEMpTrqHrls: implementation-data-type=uint8
        CAN1_ActMaxAvaEMRecpTrq: implementation-data-type=uint8
        CAN1_DrvDemEMRtapTrq: implementation-data-type=uint8
        CAN1_EMTrqModeDrvBrk: implementation-data-type=uint8
        CAN1_RetSelNonEng: implementation-data-type=uint8
        CAN1_SACtrlDev: implementation-data-type=uint8
    DT_CAN1_SG_FD1_C200_0
      element CAN1_SysPowerMode: implementation-data-type=uint8
    DT_CAN1_SG_FD1_C20_0
      4 x element, all with category=TYPE_REFERENCE, implementation-data-type=uint16:
        CAN1_DCCurr
        CAN1_DCVol
        CAN1_MaxTorqAvail
        CAN1_MinTorqAvail
    DT_CAN1_SG_FD1_C250_0
      element CAN1_EMParasLoss: implementation-data-type=uint8
      element CAN1_NFricPercTorq: implementation-data-type=uint8
    DT_CAN1_SG_FD1_C5000_0
      14 x element, all with category=TYPE_REFERENCE:
        CAN1_RC1MaxRetSpdP2: implementation-data-type=uint16
        CAN1_RC1PctTrqIdleP1: implementation-data-type=uint8
        CAN1_RC1PctTrqMaxSpdP2: implementation-data-type=uint8
        CAN1_RC1PctTrqP3: implementation-data-type=uint8
        CAN1_RC1PctTrqP4: implementation-data-type=uint8
        CAN1_RC1PctTrqPekTrqP5: implementation-data-type=uint8
        CAN1_RC1RefRetTrq: implementation-data-type=uint16
        CAN1_RC1RetCtrlMth: implementation-data-type=uint8
        CAN1_RC1RetLocat: implementation-data-type=uint8
        CAN1_RC1RetSpdIdleP1: implementation-data-type=uint16
        CAN1_RC1RetSpdP3: implementation-data-type=uint16
        CAN1_RC1RetSpdP4: implementation-data-type=uint16
        CAN1_RC1RetSpdPekTrqP5: implementation-data-type=uint16
        CAN1_RC1RetType: implementation-data-type=uint8
    DT_CAN1_SG_FD1_C5000_1
      27 x element, all with category=TYPE_REFERENCE:
        CAN1_EMDefTrqLmt: implementation-data-type=uint16
        CAN1_EMEMRefTorq: implementation-data-type=uint16
        CAN1_EMEMSpdP{2..5}: implementation-data-type=uint16
        CAN1_EMExtRSCtrlUpLmt: implementation-data-type=uint16
        CAN1_EMGainEndSpdGvn: implementation-data-type=uint16
        CAN1_EMMaxMEngOvrSP7: implementation-data-type=uint16
        CAN1_EMMaxMOvrTLmt: implementation-data-type=uint8
        CAN1_EMMomOfInertia: implementation-data-type=uint16
        CAN1_EMPercTorqIdleP1: implementation-data-type=uint8
        CAN1_EMPercTorqP{2..5}: implementation-data-type=uint8
        CAN1_EMReqSpdCtrlLoLmt: implementation-data-type=uint8
        CAN1_EMReqSpdCtrlUpLmt: implementation-data-type=uint8
        CAN1_EMReqTrqCtrlLoLmt: implementation-data-type=uint8
        CAN1_EMReqTrqCtrlUpLmt: implementation-data-type=uint8
        CAN1_EMSpdHIdleP6: implementation-data-type=uint16
        CAN1_EMSpdIdleP1: implementation-data-type=uint16
        CAN1_EMSupTSC1CtrlPG{1..4}: implementation-data-type=uint8
        CAN1_EMSupVarRTSC1MSG: implementation-data-type=uint8
    DT_CAN1_SG_FD1_C50_0
      element CAN1_ActDriveDirect: implementation-data-type=uint8
    DT_CAN1_SG_FD1_C50_1
      4 x element, all with category=TYPE_REFERENCE, implementation-data-type=uint8:
        CAN1_AccPedal1LowSW
        CAN1_AccPedalPos1
        CAN1_EEC2MSGCS
        CAN1_EEC2MSGCnt
    DT_CAN1_SG_FD1_C80_0
      element CAN1_DLEngaged: implementation-data-type=uint8
      element CAN1_ShiftPgs: implementation-data-type=uint8
    DT_CAN1_SG_FD1_CE100_0
      8 x element, all with category=TYPE_REFERENCE, implementation-data-type=uint8:
        CAN1_CFGEM1DT{0..7}
    DT_CAN1_SG_FD1_CE100_1
      5 x element, all with category=TYPE_REFERENCE:
        CAN1_CFGEM1BAMPGN: implementation-data-type=uint32
        CAN1_CFGEM1BAMRsv: implementation-data-type=uint8
        CAN1_CFGEM1BAMTNum: implementation-data-type=uint8
        CAN1_CFGEM1BAMTSize: implementation-data-type=uint16
        CAN1_CFGEM1Ctrl: implementation-data-type=uint8
    DT_CAN1_SG_FD1_CE100_2
      4 x element, all with category=TYPE_REFERENCE, implementation-data-type=uint8:
        CAN1_FDC_BCM_DVRSignalL_Cmd
        CAN1_FDC_BCM_DVRSignalR_Cmd
        CAN1_FDC_BCM_LTurnLp_Cmd
        CAN1_FDC_BCM_RTurnLp_Cmd
    DT_CAN1_SG_HRW
      4 x element, all with category=TYPE_REFERENCE, implementation-data-type=uint16:
        CAN1_WhlSpeed_FL
        CAN1_WhlSpeed_FR
        CAN1_WhlSpeed_RL
        CAN1_WhlSpeed_RR
    DT_CAN1_SG_TC1
      5 x element, all with category=TYPE_REFERENCE, implementation-data-type=uint8:
        CAN1_DrivDirF
        CAN1_DrivDirN
        CAN1_DrivDirR
        CAN1_LifeCnt
        CAN1_TransReqGear
    DT_CAN1_SG_TPMS1
      25 x element, all with category=TYPE_REFERENCE, implementation-data-type=uint8:
        CAN1_LBIBatWarn
        CAN1_LBIPressIndi
        CAN1_LBISensorFail
        CAN1_LBIWheelTmpIndi
        CAN1_LBOBatWarn
        CAN1_LBOPressIndi
        CAN1_LBOSensorFail
        CAN1_LBOWheelTmpIndi
        CAN1_LFBatWarn
        CAN1_LFPressIndi
        CAN1_LFSensorFail
        CAN1_LFWheelTmpIndi
        CAN1_RBIBatWarn
        CAN1_RBIPressIndi
        CAN1_RBISensorFail
        CAN1_RBIWheelTmpIndi
        CAN1_RBOBatWarn
        CAN1_RBOPressIndi
        CAN1_RBOSensorFail
        CAN1_RBOWheelTmpIndi
        CAN1_RFBatWarn
        CAN1_RFPressIndi
        CAN1_RFSensorFail
        CAN1_RFWheelTmpIndi
        CAN1_TPMSWarnIndi
    DT_CAN1_SG_TPMS2
      6 x element, all with category=TYPE_REFERENCE, implementation-data-type=uint8:
        CAN1_LBIWheelPress
        CAN1_LBOWheelPress
        CAN1_LFWheelPress
        CAN1_RBIWheelPress
        CAN1_RBOWheelPress
        CAN1_RFWheelPress
    DT_CAN1_SG_TPMS3
      6 x element, all with category=TYPE_REFERENCE, implementation-data-type=uint8:
        CAN1_LBIWheelTemp
        CAN1_LBOWheelTemp
        CAN1_LFWheelTemp
        CAN1_RBIWheelTemp
        CAN1_RBOWheelTemp
        CAN1_RFWheelTemp
    DT_CAN1_SG_VDC1
      element CAN1_VDCBrakeLightReq: implementation-data-type=uint8
